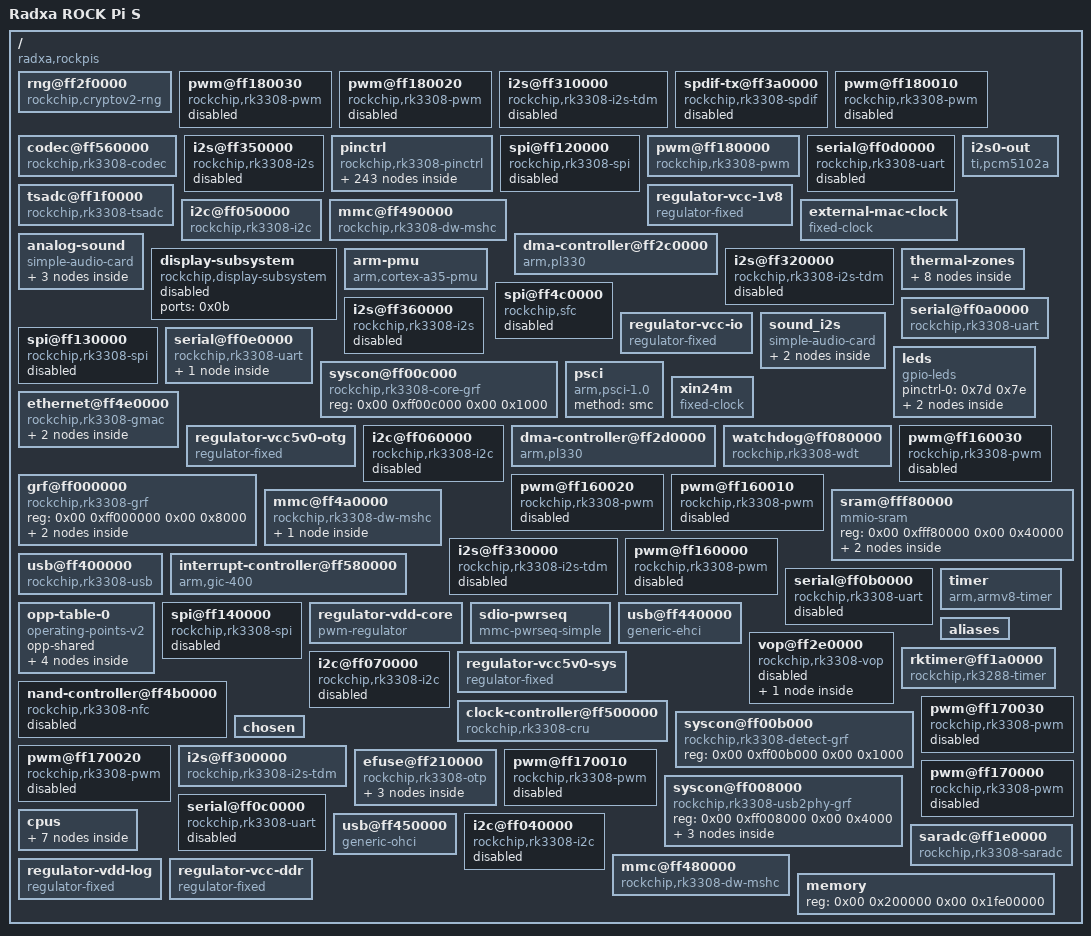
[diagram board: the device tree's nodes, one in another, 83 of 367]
/dts-v1/;

/ {
	#address-cells = <0x02>;
	model = "Radxa ROCK Pi S";
	serial-number = "f860772dc3d76db9";
	#size-cells = <0x02>;
	interrupt-parent = <0x01>;
	compatible = "radxa,rockpis", "rockchip,rk3308";

	rng@ff2f0000 {
		clock-names = "clk_crypto", "clk_crypto_apk", "aclk_crypto", "hclk_crypto";
		assigned-clocks = <0x02 0x29 0x02 0x2a 0x02 0x87 0x02 0xab>;
		assigned-clock-rates = <0x8f0d180 0x8f0d180 0xbebc200 0x5f5e100>;
		resets = <0x02 0x24>;
		clocks = <0x02 0x29 0x02 0x2a 0x02 0x87 0x02 0xab>;
		compatible = "rockchip,cryptov2-rng";
		reg = <0x00 0xff2f0000 0x00 0x4000>;
		phandle = <0x87>;
		reset-names = "reset";
	};

	pwm@ff180030 {
		pinctrl-names = "default";
		pinctrl-0 = <0x3a>;
		clock-names = "pwm", "pclk";
		clocks = <0x02 0x1a 0x02 0xce>;
		#pwm-cells = <0x03>;
		compatible = "rockchip,rk3308-pwm", "rockchip,rk3328-pwm";
		status = "disabled";
		reg = <0x00 0xff180030 0x00 0x10>;
		phandle = <0xa2>;
	};

	pwm@ff180020 {
		pinctrl-names = "default";
		pinctrl-0 = <0x39>;
		clock-names = "pwm", "pclk";
		clocks = <0x02 0x1a 0x02 0xce>;
		#pwm-cells = <0x03>;
		compatible = "rockchip,rk3308-pwm", "rockchip,rk3328-pwm";
		status = "disabled";
		reg = <0x00 0xff180020 0x00 0x10>;
		phandle = <0xa1>;
	};

	i2s@ff310000 {
		rockchip,cru = <0x02>;
		clock-names = "mclk_tx", "mclk_rx", "hclk", "mclk_tx_src", "mclk_rx_src", "mclk_root0", "mclk_root1";
		rockchip,io-multiplex;
		resets = <0x02 0x8c 0x02 0x8d>;
		interrupts = <0x00 0x31 0x04>;
		clocks = <0x02 0x50 0x02 0x52 0x02 0xa5 0x02 0x70 0x02 0x71 0x02 0x03 0x02 0x04>;
		rockchip,mclk-calibrate;
		dma-names = "tx", "rx";
		compatible = "rockchip,rk3308-i2s-tdm";
		status = "disabled";
		rockchip,grf = <0x3d>;
		reg = <0x00 0xff310000 0x00 0x1000>;
		phandle = <0xb0>;
		dmas = <0x1b 0x02 0x1b 0x03>;
		reset-names = "tx-m", "rx-m";
	};

	spdif-tx@ff3a0000 {
		pinctrl-names = "default";
		pinctrl-0 = <0x52>;
		clock-names = "mclk", "hclk";
		interrupts = <0x00 0x37 0x04>;
		clocks = <0x02 0x62 0x02 0xa2>;
		dma-names = "tx";
		compatible = "rockchip,rk3308-spdif", "rockchip,rk3066-spdif";
		status = "disabled";
		reg = <0x00 0xff3a0000 0x00 0x1000>;
		phandle = <0xb4>;
		dmas = <0x1b 0x0d>;
	};

	pwm@ff180010 {
		pinctrl-names = "default";
		pinctrl-0 = <0x38>;
		clock-names = "pwm", "pclk";
		clocks = <0x02 0x1a 0x02 0xce>;
		#pwm-cells = <0x03>;
		compatible = "rockchip,rk3308-pwm", "rockchip,rk3328-pwm";
		status = "disabled";
		reg = <0x00 0xff180010 0x00 0x10>;
		phandle = <0xa0>;
	};

	codec@ff560000 {
		rockchip,detect-grf = <0x71>;
		clock-names = "mclk_tx", "mclk_rx", "acodec";
		resets = <0x02 0x99>;
		interrupts = <0x01 0x72 0x04 0x01 0x73 0x04>;
		clocks = <0x02 0x55 0x02 0x57 0x02 0xc4>;
		#sound-dai-cells = <0x00>;
		compatible = "rockchip,rk3308-codec";
		status = "okay";
		rockchip,grf = <0x3d>;
		reg = <0x00 0xff560000 0x00 0x10000>;
		phandle = <0x80>;
		reset-names = "acodec-reset";
	};

	i2s@ff350000 {
		pinctrl-names = "default";
		pinctrl-0 = <0x4e 0x4f 0x50 0x51>;
		clock-names = "i2s_clk", "i2s_hclk";
		resets = <0x02 0x95 0x02 0x94>;
		interrupts = <0x00 0x34 0x04>;
		clocks = <0x02 0x5c 0x02 0xa8>;
		dma-names = "tx", "rx";
		compatible = "rockchip,rk3308-i2s", "rockchip,rk3066-i2s";
		status = "disabled";
		reg = <0x00 0xff350000 0x00 0x1000>;
		phandle = <0xb2>;
		dmas = <0x1b 0x08 0x1b 0x09>;
		reset-names = "reset-m", "reset-h";
	};

	pinctrl {
		pinctrl-names = "default";
		#address-cells = <0x02>;
		pinctrl-0 = <0x72>;
		#size-cells = <0x02>;
		compatible = "rockchip,rk3308-pinctrl";
		ranges;
		rockchip,grf = <0x3d>;
		phandle = <0xc1>;

		pwm9 {

			pwm9-pin-pull-down {
				rockchip,pins = <0x02 0x0b 0x02 0x79>;
				phandle = <0x105>;
			};

			pwm9-pin {
				rockchip,pins = <0x02 0x0b 0x02 0x75>;
				phandle = <0x30>;
			};
		};

		pdm_m1 {

			pdm-m1-sdi2 {
				rockchip,pins = <0x01 0x13 0x04 0x75>;
				phandle = <0xf4>;
			};

			pdm-m1-sdi0 {
				rockchip,pins = <0x01 0x15 0x04 0x75>;
				phandle = <0xf2>;
			};

			pdm-m1-clk {
				rockchip,pins = <0x01 0x0e 0x04 0x75>;
				phandle = <0xf1>;
			};

			pdm-m1-sdi3 {
				rockchip,pins = <0x01 0x12 0x04 0x75>;
				phandle = <0xf5>;
			};

			pdm-m1-sdi1 {
				rockchip,pins = <0x01 0x14 0x04 0x75>;
				phandle = <0xf3>;
			};
		};

		gmac-m1 {

			macm1-refclk-12ma {
				rockchip,pins = <0x04 0x0c 0x02 0x77>;
				phandle = <0xd3>;
			};

			macm1-refclk {
				rockchip,pins = <0x04 0x0c 0x02 0x75>;
				phandle = <0xd4>;
			};

			rmiim1-pins {
				rockchip,pins = <0x04 0x0f 0x02 0x77 0x04 0x05 0x02 0x77 0x04 0x04 0x02 0x77 0x04 0x02 0x02 0x75 0x04 0x03 0x02 0x75 0x04 0x00 0x02 0x75 0x04 0x01 0x02 0x75 0x04 0x0e 0x02 0x75 0x04 0x0d 0x02 0x75>;
				phandle = <0xd2>;
			};
		};

		spdif_out {

			spdif-out {
				rockchip,pins = <0x00 0x11 0x01 0x75>;
				phandle = <0x52>;
			};
		};

		spi2 {

			spi2-clk {
				rockchip,pins = <0x01 0x18 0x03 0x7b>;
				phandle = <0x2b>;
			};

			spi2-csn0 {
				rockchip,pins = <0x01 0x19 0x03 0x7b>;
				phandle = <0x2c>;
			};

			spi2-mosi {
				rockchip,pins = <0x01 0x17 0x03 0x7b>;
				phandle = <0x2e>;
			};

			spi2-miso {
				rockchip,pins = <0x01 0x16 0x03 0x7b>;
				phandle = <0x2d>;
			};
		};

		pcfg-pull-none-12ma {
			drive-strength = <0x0c>;
			bias-disable;
			phandle = <0x77>;
		};

		i2c1 {

			i2c1-xfer {
				rockchip,pins = <0x00 0x0b 0x01 0x78 0x00 0x0c 0x01 0x78>;
				phandle = <0x11>;
			};
		};

		pwm7 {

			pwm7-pin-pull-down {
				rockchip,pins = <0x02 0x08 0x02 0x79>;
				phandle = <0x103>;
			};

			pwm7-pin {
				rockchip,pins = <0x02 0x08 0x02 0x75>;
				phandle = <0x36>;
			};
		};

		gmac {

			mac-refclk {
				rockchip,pins = <0x01 0x0c 0x03 0x75>;
				phandle = <0xd1>;
			};

			rmii-pins {
				rockchip,pins = <0x01 0x11 0x03 0x77 0x01 0x13 0x03 0x77 0x01 0x12 0x03 0x77 0x01 0x14 0x03 0x75 0x01 0x15 0x03 0x75 0x01 0x0f 0x03 0x75 0x01 0x10 0x03 0x75 0x01 0x0e 0x03 0x75 0x01 0x0d 0x03 0x75>;
				phandle = <0x69>;
			};

			mac-refclk-12ma {
				rockchip,pins = <0x01 0x0c 0x03 0x77>;
				phandle = <0x6a>;
			};

			mac-rst {
				rockchip,pins = <0x00 0x07 0x00 0x75>;
				phandle = <0x6c>;
			};
		};

		i2s_8ch_0 {

			i2s-8ch-0-sdo2 {
				rockchip,pins = <0x02 0x0b 0x01 0x75>;
				phandle = <0x4b>;
			};

			i2s-8ch-0-sdo0 {
				rockchip,pins = <0x02 0x09 0x01 0x75>;
				phandle = <0x49>;
			};

			i2s-8ch-0-sdi2 {
				rockchip,pins = <0x02 0x0f 0x01 0x75>;
				phandle = <0x47>;
			};

			i2s-8ch-0-sdi0 {
				rockchip,pins = <0x02 0x0d 0x01 0x75>;
				phandle = <0x45>;
			};

			i2s-8ch-0-sdo3 {
				rockchip,pins = <0x02 0x0c 0x01 0x75>;
				phandle = <0x4c>;
			};

			i2s-8ch-0-sdo1 {
				rockchip,pins = <0x02 0x0a 0x01 0x75>;
				phandle = <0x4a>;
			};

			i2s-8ch-0-lrcktx {
				rockchip,pins = <0x02 0x07 0x01 0x75>;
				phandle = <0x43>;
			};

			i2s-8ch-0-sdi3 {
				rockchip,pins = <0x02 0x10 0x01 0x75>;
				phandle = <0x48>;
			};

			i2s-8ch-0-lrckrx {
				rockchip,pins = <0x02 0x08 0x01 0x75>;
				phandle = <0x44>;
			};

			i2s-8ch-0-mclk {
				rockchip,pins = <0x02 0x04 0x01 0x75>;
				phandle = <0x4d>;
			};

			i2s-8ch-0-sclktx {
				rockchip,pins = <0x02 0x05 0x01 0x75>;
				phandle = <0x41>;
			};

			i2s-8ch-0-sdi1 {
				rockchip,pins = <0x02 0x0e 0x01 0x75>;
				phandle = <0x46>;
			};

			i2s-8ch-0-sclkrx {
				rockchip,pins = <0x02 0x06 0x01 0x75>;
				phandle = <0x42>;
			};
		};

		gpio@ff230000 {
			gpio-controller;
			gpio-line-names = "", "", "", "", "", "", "", "", "", "", "", "", "", "", "", "", "", "", "", "", "", "", "header1-pin21 [GPIO1_C6]", "header1-pin19 [GPIO1_C7]", "header1-pin23 [GPIO1_D0]", "header1-pin24 [GPIO1_D1]", "", "", "", "", "", "";
			interrupts = <0x00 0x29 0x04>;
			clocks = <0x02 0xd8>;
			compatible = "rockchip,gpio-bank";
			#interrupt-cells = <0x02>;
			reg = <0x00 0xff230000 0x00 0x100>;
			phandle = <0xc2>;
			#gpio-cells = <0x02>;
			interrupt-controller;
		};

		i2s_8ch_1_m0 {

			i2s-8ch-1-m0-sdo3_sdi1 {
				rockchip,pins = <0x01 0x0a 0x02 0x75>;
				phandle = <0xe0>;
			};

			i2s-8ch-1-m0-sdo0 {
				rockchip,pins = <0x01 0x07 0x02 0x75>;
				phandle = <0xdd>;
			};

			i2s-8ch-1-m0-sdo1-sdi3 {
				rockchip,pins = <0x01 0x08 0x02 0x75>;
				phandle = <0xde>;
			};

			i2s-8ch-1-m0-lrcktx {
				rockchip,pins = <0x01 0x05 0x02 0x75>;
				phandle = <0xdb>;
			};

			i2s-8ch-1-m0-lrckrx {
				rockchip,pins = <0x01 0x06 0x02 0x75>;
				phandle = <0xdc>;
			};

			i2s-8ch-1-m0-sdi0 {
				rockchip,pins = <0x01 0x0b 0x02 0x75>;
				phandle = <0xe1>;
			};

			i2s-8ch-1-m0-sclktx {
				rockchip,pins = <0x01 0x03 0x02 0x75>;
				phandle = <0xd9>;
			};

			i2s-8ch-1-m0-sclkrx {
				rockchip,pins = <0x01 0x04 0x02 0x75>;
				phandle = <0xda>;
			};

			i2s-8ch-1-m0-sdo2-sdi2 {
				rockchip,pins = <0x01 0x09 0x02 0x75>;
				phandle = <0xdf>;
			};

			i2s-8ch-1-m0-mclk {
				rockchip,pins = <0x01 0x02 0x02 0x75>;
				phandle = <0xd8>;
			};
		};

		spi0 {

			spi0-miso {
				rockchip,pins = <0x02 0x00 0x02 0x7b>;
				phandle = <0x25>;
			};

			spi0-csn0 {
				rockchip,pins = <0x02 0x03 0x02 0x7b>;
				phandle = <0x24>;
			};

			spi0-clk {
				rockchip,pins = <0x02 0x02 0x02 0x7b>;
				phandle = <0x23>;
			};

			spi0-mosi {
				rockchip,pins = <0x02 0x01 0x02 0x7b>;
				phandle = <0x26>;
			};
		};

		pcfg-pull-down-4ma {
			drive-strength = <0x04>;
			bias-pull-down;
			phandle = <0xc7>;
		};

		pwm5 {

			pwm5-pin-pull-down {
				rockchip,pins = <0x00 0x11 0x02 0x79>;
				phandle = <0x101>;
			};

			pwm5-pin {
				rockchip,pins = <0x00 0x11 0x02 0x75>;
				phandle = <0x34>;
			};
		};

		pcfg-pull-none-2ma {
			drive-strength = <0x02>;
			bias-disable;
			phandle = <0xc5>;
		};

		pwm10 {

			pwm10-pin-pull-down {
				rockchip,pins = <0x02 0x0c 0x02 0x79>;
				phandle = <0x106>;
			};

			pwm10-pin {
				rockchip,pins = <0x02 0x0c 0x02 0x75>;
				phandle = <0x31>;
			};
		};

		pcfg-pull-down {
			bias-pull-down;
			phandle = <0x79>;
		};

		uart4 {

			uart4-cts {
				rockchip,pins = <0x04 0x06 0x01 0x75>;
				phandle = <0x1d>;
			};

			uart4-xfer {
				rockchip,pins = <0x04 0x09 0x01 0x7c 0x04 0x08 0x01 0x7c>;
				phandle = <0x1c>;
			};

			uart4-rts-pin {
				rockchip,pins = <0x04 0x07 0x00 0x75>;
				phandle = <0x118>;
			};

			uart4-rts {
				rockchip,pins = <0x04 0x07 0x01 0x75>;
				phandle = <0x1e>;
			};
		};

		uart2-m0 {

			uart2m0-xfer {
				rockchip,pins = <0x01 0x17 0x02 0x7c 0x01 0x16 0x02 0x7c>;
				phandle = <0x19>;
			};
		};

		pwm3 {

			pwm3-pin-pull-down {
				rockchip,pins = <0x00 0x10 0x01 0x79>;
				phandle = <0xff>;
			};

			pwm3-pin {
				rockchip,pins = <0x00 0x10 0x01 0x75>;
				phandle = <0x3a>;
			};
		};

		lcdc {

			lcdc-rgb888-m1 {
				rockchip,pins = <0x03 0x06 0x03 0x75 0x03 0x07 0x03 0x75 0x03 0x08 0x03 0x75 0x03 0x09 0x03 0x75 0x03 0x0a 0x04 0x75 0x03 0x0b 0x04 0x75>;
				phandle = <0x11a>;
			};

			lcdc-ctl {
				rockchip,pins = <0x01 0x00 0x01 0x77 0x01 0x01 0x01 0x75 0x01 0x02 0x01 0x75 0x01 0x03 0x01 0x75 0x01 0x04 0x01 0x75 0x01 0x05 0x01 0x75 0x01 0x06 0x01 0x75 0x01 0x07 0x01 0x75 0x01 0x08 0x01 0x75 0x01 0x09 0x01 0x75 0x01 0x0a 0x01 0x75 0x01 0x0b 0x01 0x75 0x01 0x0c 0x01 0x75 0x01 0x0d 0x01 0x75 0x01 0x0e 0x01 0x75 0x01 0x0f 0x01 0x75 0x01 0x10 0x01 0x75 0x01 0x11 0x01 0x75 0x01 0x12 0x01 0x75 0x01 0x13 0x01 0x75 0x01 0x14 0x01 0x75 0x01 0x15 0x01 0x75>;
				phandle = <0x40>;
			};

			lcdc-rgb888-m0 {
				rockchip,pins = <0x01 0x16 0x06 0x75 0x01 0x17 0x06 0x75 0x02 0x09 0x03 0x75 0x02 0x0a 0x03 0x75 0x02 0x0f 0x03 0x75 0x02 0x10 0x03 0x75>;
				phandle = <0x119>;
			};
		};

		gpio@ff240000 {
			gpio-controller;
			gpio-line-names = "header1-pin10 [GPIO2_A0]", "header1-pin8 [GPIO2_A1]", "", "", "header1-pin7 [GPIO2_A4]", "header1-pin12 [GPIO2_A5]", "header2-pin46 [GPIO2_A6]", "header1-pin22 [GPIO1_A7]", "header2-pin45 [GPIO2_B0]", "header1-pin18 [GPIO2_B1]", "header1-pin16 [GPIO2_B2]", "header2-pin44 [GPIO2_B3]", "header2-pin43 [GPIO2_B4]", "header2-pin28 [GPIO2_B5]", "header2-pin30 [GPIO2_B6]", "header2-pin32 [GPIO2_B7]", "header2-pin34 [GPIO2_C0]", "", "", "", "", "", "", "", "", "", "", "", "", "", "", "";
			interrupts = <0x00 0x2a 0x04>;
			clocks = <0x02 0xd9>;
			compatible = "rockchip,gpio-bank";
			#interrupt-cells = <0x02>;
			reg = <0x00 0xff240000 0x00 0x100>;
			phandle = <0xc3>;
			#gpio-cells = <0x02>;
			interrupt-controller;
		};

		pcfg-pull-none-8ma {
			drive-strength = <0x08>;
			bias-disable;
			phandle = <0x73>;
		};

		uart3-m1 {

			uart3m1-xfer {
				rockchip,pins = <0x00 0x12 0x03 0x7c 0x00 0x11 0x03 0x7c>;
				phandle = <0x117>;
			};
		};

		leds {

			heartbeat-led {
				rockchip,pins = <0x00 0x05 0x00 0x75>;
				phandle = <0x7e>;
			};

			green-led {
				rockchip,pins = <0x00 0x06 0x00 0x75>;
				phandle = <0x7d>;
			};
		};

		pwm1 {

			pwm1-pin {
				rockchip,pins = <0x00 0x0e 0x01 0x75>;
				phandle = <0x38>;
			};

			pwm1-pin-pull-down {
				rockchip,pins = <0x00 0x0e 0x01 0x79>;
				phandle = <0xfd>;
			};
		};

		tsadc {

			tsadc-otp-out {
				rockchip,pins = <0x00 0x0a 0x01 0x75>;
				phandle = <0x3f>;
			};

			tsadc-otp-pin {
				rockchip,pins = <0x00 0x0a 0x00 0x75>;
				phandle = <0x3e>;
			};
		};

		i2c3-m2 {

			i2c3m2-xfer {
				rockchip,pins = <0x02 0x01 0x03 0x78 0x02 0x00 0x03 0x78>;
				phandle = <0xd6>;
			};
		};

		uart0 {

			uart0-rts-pin {
				rockchip,pins = <0x02 0x03 0x00 0x75>;
				phandle = <0x115>;
			};

			uart0-cts {
				rockchip,pins = <0x02 0x02 0x01 0x75>;
				phandle = <0x113>;
			};

			uart0-rts {
				rockchip,pins = <0x02 0x03 0x01 0x75>;
				phandle = <0x114>;
			};

			uart0-xfer {
				rockchip,pins = <0x02 0x01 0x01 0x7c 0x02 0x00 0x01 0x7c>;
				phandle = <0x15>;
			};
		};

		emmc {

			emmc-rstn {
				rockchip,pins = <0x03 0x0a 0x02 0x75>;
				phandle = <0xcd>;
			};

			emmc-clk {
				rockchip,pins = <0x03 0x09 0x02 0x73>;
				phandle = <0x5a>;
			};

			emmc-bus1 {
				rockchip,pins = <0x03 0x00 0x02 0x74>;
				phandle = <0xce>;
			};

			emmc-bus8 {
				rockchip,pins = <0x03 0x00 0x02 0x74 0x03 0x01 0x02 0x74 0x03 0x02 0x02 0x74 0x03 0x03 0x02 0x74 0x03 0x04 0x02 0x74 0x03 0x05 0x02 0x74 0x03 0x06 0x02 0x74 0x03 0x07 0x02 0x74>;
				phandle = <0x59>;
			};

			emmc-bus4 {
				rockchip,pins = <0x03 0x00 0x02 0x74 0x03 0x01 0x02 0x74 0x03 0x02 0x02 0x74 0x03 0x03 0x02 0x74>;
				phandle = <0xcf>;
			};

			emmc-pwren {
				rockchip,pins = <0x03 0x0b 0x02 0x75>;
				phandle = <0xcc>;
			};

			emmc-cmd {
				rockchip,pins = <0x03 0x08 0x02 0x74>;
				phandle = <0x5b>;
			};
		};

		pdm_m2 {

			pdm-m2-sdi3 {
				rockchip,pins = <0x02 0x10 0x02 0x75>;
				phandle = <0xfb>;
			};

			pdm-m2-sdi1 {
				rockchip,pins = <0x02 0x0e 0x02 0x75>;
				phandle = <0xf9>;
			};

			pdm-m2-clk {
				rockchip,pins = <0x02 0x06 0x02 0x75>;
				phandle = <0xf7>;
			};

			pdm-m2-sdi2 {
				rockchip,pins = <0x02 0x0f 0x02 0x75>;
				phandle = <0xfa>;
			};

			pdm-m2-sdi0 {
				rockchip,pins = <0x02 0x0d 0x02 0x75>;
				phandle = <0xf8>;
			};

			pdm-m2-clkm {
				rockchip,pins = <0x02 0x04 0x03 0x75>;
				phandle = <0xf6>;
			};
		};

		spdif_in {

			spdif-in {
				rockchip,pins = <0x00 0x12 0x01 0x75>;
				phandle = <0x10e>;
			};
		};

		pcfg-output-high {
			output-high;
			phandle = <0xc8>;
		};

		pcfg-pull-up {
			phandle = <0x7c>;
			bias-pull-up;
		};

		i2c3-m0 {

			i2c3m0-xfer {
				rockchip,pins = <0x00 0x0f 0x02 0x78 0x00 0x10 0x02 0x78>;
				phandle = <0x13>;
			};
		};

		pcfg-input {
			phandle = <0xcb>;
			input-enable;
		};

		pcfg-pull-up-2ma {
			drive-strength = <0x02>;
			phandle = <0xc6>;
			bias-pull-up;
		};

		i2c2 {

			i2c2-xfer {
				rockchip,pins = <0x02 0x02 0x03 0x78 0x02 0x03 0x03 0x78>;
				phandle = <0x12>;
			};
		};

		pwm8 {

			pwm8-pin {
				rockchip,pins = <0x02 0x0a 0x02 0x75>;
				phandle = <0x2f>;
			};

			pwm8-pin-pull-down {
				rockchip,pins = <0x02 0x0a 0x02 0x79>;
				phandle = <0x104>;
			};
		};

		i2s_2ch_0 {

			i2s-2ch-0-sdo {
				rockchip,pins = <0x04 0x0f 0x01 0x75>;
				phandle = <0x51>;
			};

			i2s-2ch-0-sclk {
				rockchip,pins = <0x04 0x0d 0x01 0x75>;
				phandle = <0x4e>;
			};

			i2s-2ch-0-sdi {
				rockchip,pins = <0x04 0x10 0x01 0x75>;
				phandle = <0x50>;
			};

			i2s-2ch-0-lrck {
				rockchip,pins = <0x04 0x0e 0x01 0x75>;
				phandle = <0x4f>;
			};

			i2s-2ch-0-mclk {
				rockchip,pins = <0x04 0x0c 0x01 0x75>;
				phandle = <0xd7>;
			};
		};

		pcfg-pull-none {
			bias-disable;
			phandle = <0x75>;
		};

		pdm_m0 {

			pdm-m0-clk {
				rockchip,pins = <0x01 0x04 0x03 0x75>;
				phandle = <0xec>;
			};

			pdm-m0-sdi2 {
				rockchip,pins = <0x01 0x09 0x03 0x75>;
				phandle = <0xef>;
			};

			pdm-m0-sdi0 {
				rockchip,pins = <0x01 0x0b 0x03 0x75>;
				phandle = <0xed>;
			};

			pdm-m0-sdi3 {
				rockchip,pins = <0x01 0x08 0x03 0x75>;
				phandle = <0xf0>;
			};

			pdm-m0-sdi1 {
				rockchip,pins = <0x01 0x0a 0x03 0x75>;
				phandle = <0xee>;
			};
		};

		pcfg-pull-none-4ma {
			drive-strength = <0x04>;
			bias-disable;
			phandle = <0x7a>;
		};

		i2s_8ch_1_m1 {

			i2s-8ch-1-m1-sdo0 {
				rockchip,pins = <0x01 0x11 0x02 0x75>;
				phandle = <0xe7>;
			};

			i2s-8ch-1-m1-sdo2-sdi2 {
				rockchip,pins = <0x01 0x13 0x02 0x75>;
				phandle = <0xe9>;
			};

			i2s-8ch-1-m1-sdi0 {
				rockchip,pins = <0x01 0x15 0x02 0x75>;
				phandle = <0xeb>;
			};

			i2s-8ch-1-m1-lrcktx {
				rockchip,pins = <0x01 0x0f 0x02 0x75>;
				phandle = <0xe5>;
			};

			i2s-8ch-1-m1-lrckrx {
				rockchip,pins = <0x01 0x10 0x02 0x75>;
				phandle = <0xe6>;
			};

			i2s-8ch-1-m1-sdo3_sdi1 {
				rockchip,pins = <0x01 0x14 0x02 0x75>;
				phandle = <0xea>;
			};

			i2s-8ch-1-m1-sclktx {
				rockchip,pins = <0x01 0x0d 0x02 0x75>;
				phandle = <0xe3>;
			};

			i2s-8ch-1-m1-sclkrx {
				rockchip,pins = <0x01 0x0e 0x02 0x75>;
				phandle = <0xe4>;
			};

			i2s-8ch-1-m1-mclk {
				rockchip,pins = <0x01 0x0c 0x02 0x75>;
				phandle = <0xe2>;
			};

			i2s-8ch-1-m1-sdo1-sdi3 {
				rockchip,pins = <0x01 0x12 0x02 0x75>;
				phandle = <0xe8>;
			};
		};

		sfc {

			sfc-bus4 {
				rockchip,pins = <0x03 0x00 0x03 0x75 0x03 0x01 0x03 0x75 0x03 0x02 0x03 0x75 0x03 0x03 0x03 0x75>;
				phandle = <0x6f>;
			};

			sfc-bus2 {
				rockchip,pins = <0x03 0x00 0x03 0x75 0x03 0x01 0x03 0x75>;
				phandle = <0xd0>;
			};

			sfc-clk {
				rockchip,pins = <0x03 0x05 0x03 0x75>;
				phandle = <0x6d>;
			};

			sfc-cs0 {
				rockchip,pins = <0x03 0x04 0x03 0x75>;
				phandle = <0x6e>;
			};
		};

		spi1 {

			spi1-miso {
				rockchip,pins = <0x03 0x0a 0x03 0x7b>;
				phandle = <0x29>;
			};

			spi1-csn0 {
				rockchip,pins = <0x03 0x0d 0x03 0x7b>;
				phandle = <0x28>;
			};

			spi1-mosi {
				rockchip,pins = <0x03 0x0c 0x03 0x7b>;
				phandle = <0x2a>;
			};

			spi1-clk {
				rockchip,pins = <0x03 0x0b 0x03 0x7b>;
				phandle = <0x27>;
			};
		};

		sdio-pwrseq {

			wifi-host-wake {
				rockchip,pins = <0x00 0x00 0x00 0x79>;
				phandle = <0x61>;
			};

			wifi-enable-h {
				rockchip,pins = <0x00 0x02 0x00 0x75>;
				phandle = <0x81>;
			};
		};

		bluetooth {

			bt-reg-on {
				rockchip,pins = <0x04 0x0b 0x00 0x75>;
				phandle = <0x20>;
			};

			host-wake-bt {
				rockchip,pins = <0x04 0x0a 0x00 0x75>;
				phandle = <0x22>;
			};

			bt-wake-host {
				rockchip,pins = <0x04 0x0c 0x00 0x79>;
				phandle = <0x21>;
			};
		};

		usb {

			otg-vbus-drv {
				rockchip,pins = <0x00 0x15 0x00 0x75>;
				phandle = <0x83>;
			};
		};

		pcfg-pull-none-smt {
			bias-disable;
			input-schmitt-enable;
			phandle = <0x78>;
		};

		gpio@ff250000 {
			gpio-controller;
			gpio-line-names = "", "", "", "", "", "", "", "", "", "", "header2-pin42 [GPIO3_B2]", "header2-pin41 [GPIO3_B3]", "header2-pin40 [GPIO3_B4]", "header2-pin39 [GPIO3_B5]", "", "", "", "", "", "", "", "", "", "", "", "", "", "", "", "", "", "";
			interrupts = <0x00 0x2b 0x04>;
			clocks = <0x02 0xda>;
			compatible = "rockchip,gpio-bank";
			#interrupt-cells = <0x02>;
			reg = <0x00 0xff250000 0x00 0x100>;
			phandle = <0xc4>;
			#gpio-cells = <0x02>;
			interrupt-controller;
		};

		sdmmc {

			sdmmc-bus1 {
				rockchip,pins = <0x04 0x18 0x01 0x7b>;
				phandle = <0x109>;
			};

			sdmmc-det {
				rockchip,pins = <0x00 0x03 0x01 0x7b>;
				phandle = <0x57>;
			};

			sdmmc-pwren {
				rockchip,pins = <0x04 0x1e 0x01 0x7a>;
				phandle = <0x108>;
			};

			sdmmc-bus4 {
				rockchip,pins = <0x04 0x18 0x01 0x7b 0x04 0x19 0x01 0x7b 0x04 0x1a 0x01 0x7b 0x04 0x1b 0x01 0x7b>;
				phandle = <0x58>;
			};

			sdmmc-cmd {
				rockchip,pins = <0x04 0x1c 0x01 0x7b>;
				phandle = <0x56>;
			};

			sdmmc-clk {
				rockchip,pins = <0x04 0x1d 0x01 0x7a>;
				phandle = <0x55>;
			};
		};

		i2c0 {

			i2c0-xfer {
				rockchip,pins = <0x01 0x18 0x02 0x78 0x01 0x19 0x02 0x78>;
				phandle = <0x10>;
			};
		};

		pwm6 {

			pwm6-pin {
				rockchip,pins = <0x00 0x12 0x02 0x75>;
				phandle = <0x35>;
			};

			pwm6-pin-pull-down {
				rockchip,pins = <0x00 0x12 0x02 0x79>;
				phandle = <0x102>;
			};
		};

		pwm11 {

			pwm11-pin-pull-down {
				rockchip,pins = <0x02 0x10 0x04 0x79>;
				phandle = <0x107>;
			};

			pwm11-pin {
				rockchip,pins = <0x02 0x10 0x04 0x75>;
				phandle = <0x32>;
			};
		};

		sdio {

			sdio-intn {
				rockchip,pins = <0x00 0x00 0x01 0x73>;
				phandle = <0x10c>;
			};

			sdio-cmd {
				rockchip,pins = <0x04 0x04 0x01 0x74>;
				phandle = <0x5d>;
			};

			sdio-bus1 {
				rockchip,pins = <0x04 0x00 0x01 0x74>;
				phandle = <0x10d>;
			};

			sdio-clk {
				rockchip,pins = <0x04 0x05 0x01 0x73>;
				phandle = <0x5e>;
			};

			sdio-bus4 {
				rockchip,pins = <0x04 0x00 0x01 0x74 0x04 0x01 0x01 0x74 0x04 0x02 0x01 0x74 0x04 0x03 0x01 0x74>;
				phandle = <0x5c>;
			};

			sdio-wrpt {
				rockchip,pins = <0x00 0x01 0x01 0x73>;
				phandle = <0x10b>;
			};

			sdio-pwren {
				rockchip,pins = <0x00 0x02 0x01 0x73>;
				phandle = <0x10a>;
			};
		};

		pcfg-input-high {
			phandle = <0xca>;
			bias-pull-up;
			input-enable;
		};

		flash {

			flash-bus8 {
				rockchip,pins = <0x03 0x00 0x01 0x76 0x03 0x01 0x01 0x76 0x03 0x02 0x01 0x76 0x03 0x03 0x01 0x76 0x03 0x04 0x01 0x76 0x03 0x05 0x01 0x76 0x03 0x06 0x01 0x76 0x03 0x07 0x01 0x76>;
				phandle = <0x63>;
			};

			flash-rdn {
				rockchip,pins = <0x03 0x0a 0x01 0x75>;
				phandle = <0x66>;
			};

			flash-ale {
				rockchip,pins = <0x03 0x0b 0x01 0x75>;
				phandle = <0x62>;
			};

			flash-csn0 {
				rockchip,pins = <0x03 0x0d 0x01 0x75>;
				phandle = <0x65>;
			};

			flash-rdy {
				rockchip,pins = <0x03 0x0c 0x01 0x75>;
				phandle = <0x67>;
			};

			flash-cle {
				rockchip,pins = <0x03 0x09 0x01 0x75>;
				phandle = <0x64>;
			};

			flash-wrn {
				rockchip,pins = <0x03 0x08 0x01 0x75>;
				phandle = <0x68>;
			};
		};

		pcfg-pull-up-8ma {
			drive-strength = <0x08>;
			phandle = <0x74>;
			bias-pull-up;
		};

		uart2-m1 {

			uart2m1-xfer {
				rockchip,pins = <0x04 0x1b 0x02 0x7c 0x04 0x1a 0x02 0x7c>;
				phandle = <0x116>;
			};
		};

		pwm4 {

			pwm4-pin {
				rockchip,pins = <0x00 0x01 0x02 0x75>;
				phandle = <0x33>;
			};

			pwm4-pin-pull-down {
				rockchip,pins = <0x00 0x01 0x02 0x79>;
				phandle = <0x100>;
			};
		};

		uart3 {

			uart3-xfer {
				rockchip,pins = <0x03 0x0d 0x04 0x7c 0x03 0x0c 0x04 0x7c>;
				phandle = <0x1a>;
			};
		};

		pcfg-pull-up-12ma {
			drive-strength = <0x0c>;
			phandle = <0x76>;
			bias-pull-up;
		};

		pcfg-output-low {
			phandle = <0xc9>;
			output-low;
		};

		pwm2 {

			pwm2-pin {
				rockchip,pins = <0x00 0x0f 0x01 0x75>;
				phandle = <0x39>;
			};

			pwm2-pin-pull-down {
				rockchip,pins = <0x00 0x0f 0x01 0x79>;
				phandle = <0xfe>;
			};
		};

		gpio@ff220000 {
			gpio-controller;
			gpio-line-names = "", "", "", "", "", "", "", "", "", "", "", "header1-pin3 [GPIO0_B3]", "header1-pin5 [GPIO0_B4]", "", "", "header1-pin11 [GPIO0_B7]", "header1-pin13 [GPIO0_C0]", "header1-pin15 [GPIO0_C1]", "", "", "", "", "", "", "", "", "", "", "", "", "", "";
			interrupts = <0x00 0x28 0x04>;
			clocks = <0x02 0xd7>;
			compatible = "rockchip,gpio-bank";
			#interrupt-cells = <0x02>;
			reg = <0x00 0xff220000 0x00 0x100>;
			phandle = <0x60>;
			#gpio-cells = <0x02>;
			interrupt-controller;
		};

		uart1 {

			uart1-cts {
				rockchip,pins = <0x01 0x16 0x01 0x75>;
				phandle = <0x17>;
			};

			uart1-rts {
				rockchip,pins = <0x01 0x17 0x01 0x75>;
				phandle = <0x18>;
			};

			uart1-xfer {
				rockchip,pins = <0x01 0x19 0x01 0x7c 0x01 0x18 0x01 0x7c>;
				phandle = <0x16>;
			};
		};

		gpio@ff260000 {
			gpio-controller;
			interrupts = <0x00 0x2c 0x04>;
			clocks = <0x02 0xdb>;
			compatible = "rockchip,gpio-bank";
			#interrupt-cells = <0x02>;
			reg = <0x00 0xff260000 0x00 0x100>;
			phandle = <0x1f>;
			#gpio-cells = <0x02>;
			interrupt-controller;
		};

		spi1-m1 {

			spi1m1-csn0 {
				rockchip,pins = <0x02 0x09 0x02 0x7b>;
				phandle = <0x112>;
			};

			spi1m1-clk {
				rockchip,pins = <0x02 0x07 0x02 0x7b>;
				phandle = <0x111>;
			};

			spi1m1-mosi {
				rockchip,pins = <0x02 0x05 0x02 0x7b>;
				phandle = <0x110>;
			};

			spi1m1-miso {
				rockchip,pins = <0x02 0x04 0x02 0x7b>;
				phandle = <0x10f>;
			};
		};

		pcfg-pull-up-4ma {
			drive-strength = <0x04>;
			phandle = <0x7b>;
			bias-pull-up;
		};

		pwm0 {

			pwm0-pin-pull-down {
				rockchip,pins = <0x00 0x0d 0x01 0x79>;
				phandle = <0x37>;
			};

			pwm0-pin {
				rockchip,pins = <0x00 0x0d 0x01 0x75>;
				phandle = <0xfc>;
			};
		};

		rtc {

			rtc-32k {
				rockchip,pins = <0x00 0x13 0x01 0x75>;
				phandle = <0x72>;
			};
		};

		i2c3-m1 {

			i2c3m1-xfer {
				rockchip,pins = <0x03 0x0c 0x02 0x78 0x03 0x0d 0x02 0x78>;
				phandle = <0xd5>;
			};
		};
	};

	spi@ff120000 {
		pinctrl-names = "default";
		#address-cells = <0x01>;
		pinctrl-0 = <0x23 0x24 0x25 0x26>;
		clock-names = "spiclk", "apb_pclk";
		interrupts = <0x00 0x0f 0x04>;
		clocks = <0x02 0x1b 0x02 0xcf>;
		#size-cells = <0x00>;
		dma-names = "tx", "rx";
		compatible = "rockchip,rk3308-spi", "rockchip,rk3066-spi";
		status = "disabled";
		reg = <0x00 0xff120000 0x00 0x1000>;
		phandle = <0x95>;
		dmas = <0x14 0x00 0x14 0x01>;
	};

	pwm@ff180000 {
		pinctrl-names = "default";
		pinctrl-0 = <0x37>;
		clock-names = "pwm", "pclk";
		clocks = <0x02 0x1a 0x02 0xce>;
		#pwm-cells = <0x03>;
		compatible = "rockchip,rk3308-pwm", "rockchip,rk3328-pwm";
		status = "okay";
		reg = <0x00 0xff180000 0x00 0x10>;
		phandle = <0x84>;
	};

	serial@ff0d0000 {
		reg-io-width = <0x04>;
		pinctrl-names = "default";
		pinctrl-0 = <0x1a>;
		clock-names = "baudclk", "apb_pclk";
		interrupts = <0x00 0x15 0x04>;
		clocks = <0x02 0x14 0x02 0xc8>;
		dma-names = "tx", "rx";
		compatible = "rockchip,rk3308-uart", "snps,dw-apb-uart";
		status = "disabled";
		reg = <0x00 0xff0d0000 0x00 0x100>;
		phandle = <0x93>;
		dmas = <0x14 0x0a 0x14 0x0b>;
		reg-shift = <0x02>;
	};

	i2s0-out {
		#sound-dai-cells = <0x00>;
		compatible = "ti,pcm5102a";
		status = "okay";
		phandle = <0x11f>;
	};

	tsadc@ff1f0000 {
		pinctrl-names = "gpio", "otpout";
		pinctrl-0 = <0x3e>;
		clock-names = "tsadc", "apb_pclk";
		rockchip,hw-tshut-polarity = <0x01>;
		assigned-clocks = <0x02 0x24>;
		assigned-clock-rates = <0xc350>;
		resets = <0x02 0x48>;
		interrupts = <0x00 0x26 0x04>;
		rockchip,hw-tshut-mode = <0x00>;
		clocks = <0x02 0x24 0x02 0xd3>;
		#thermal-sensor-cells = <0x01>;
		compatible = "rockchip,rk3308-tsadc";
		pinctrl-1 = <0x3f>;
		status = "okay";
		rockchip,grf = <0x3d>;
		reg = <0x00 0xff1f0000 0x00 0x100>;
		phandle = <0x3b>;
		reset-names = "tsadc-apb";
		rockchip,hw-tshut-temp = <0x1d4c0>;
	};

	regulator-vcc-1v8 {
		regulator-max-microvolt = <0x1b7740>;
		regulator-boot-on;
		regulator-always-on;
		regulator-min-microvolt = <0x1b7740>;
		regulator-name = "vcc_1v8";
		compatible = "regulator-fixed";
		phandle = <0x0d>;
		vin-supply = <0x0c>;
	};

	i2c@ff050000 {
		pinctrl-names = "default";
		#address-cells = <0x01>;
		pinctrl-0 = <0x11>;
		clock-names = "i2c", "pclk";
		interrupts = <0x00 0x0c 0x04>;
		clocks = <0x02 0x17 0x02 0xcb>;
		#size-cells = <0x00>;
		compatible = "rockchip,rk3308-i2c", "rockchip,rk3399-i2c";
		status = "okay";
		reg = <0x00 0xff050000 0x00 0x1000>;
		phandle = <0x8c>;
	};

	mmc@ff490000 {
		fifo-depth = <0x100>;
		pinctrl-names = "default";
		pinctrl-0 = <0x59 0x5a 0x5b>;
		clock-names = "biu", "ciu", "ciu-drive", "ciu-sample";
		cap-sd-highspeed;
		bus-width = <0x08>;
		non-removable;
		no-sdio;
		interrupts = <0x00 0x4d 0x04>;
		clocks = <0x02 0x9c 0x02 0x3a 0x02 0x3b 0x02 0x3c>;
		vmmc-supply = <0x0c>;
		compatible = "rockchip,rk3308-dw-mshc", "rockchip,rk3288-dw-mshc";
		status = "okay";
		reg = <0x00 0xff490000 0x00 0x4000>;
		phandle = <0xb9>;
		max-frequency = <0x8f0d180>;
		cap-mmc-highspeed;
	};

	external-mac-clock {
		clock-output-names = "mac_clkin";
		#clock-cells = <0x00>;
		clock-frequency = <0x2faf080>;
		compatible = "fixed-clock";
		phandle = <0x86>;
	};

	dma-controller@ff2c0000 {
		clock-names = "apb_pclk";
		interrupts = <0x00 0x00 0x04 0x00 0x01 0x04>;
		clocks = <0x02 0x8a>;
		arm,pl330-periph-burst;
		compatible = "arm,pl330", "arm,primecell";
		reg = <0x00 0xff2c0000 0x00 0x4000>;
		phandle = <0x14>;
		#dma-cells = <0x01>;
	};

	analog-sound {
		simple-audio-card,name = "analog";
		simple-audio-card,format = "i2s";
		simple-audio-card,widgets = "Headphone", "Headphones";
		simple-audio-card,codec-hp-det;
		compatible = "simple-audio-card";
		phandle = <0x11b>;
		simple-audio-card,mclk-fs = <0x100>;

		simple-audio-card,dai-link@1 {
			format = "i2s";

			cpu {
				sound-dai = <0x7f>;
			};

			codec {
				sound-dai = <0x80>;
			};
		};
	};

	display-subsystem {
		ports = <0x0b>;
		compatible = "rockchip,display-subsystem";
		status = "disabled";
		phandle = <0x85>;
	};

	i2s@ff320000 {
		clock-names = "mclk_tx", "mclk_rx", "hclk";
		resets = <0x02 0x8f 0x02 0x90>;
		interrupts = <0x00 0x32 0x04>;
		clocks = <0x02 0x54 0x02 0x56 0x02 0xa6>;
		dma-names = "rx", "tx";
		#sound-dai-cells = <0x00>;
		compatible = "rockchip,rk3308-i2s-tdm";
		status = "disabled";
		rockchip,grf = <0x3d>;
		reg = <0x00 0xff320000 0x00 0x1000>;
		phandle = <0x7f>;
		dmas = <0x1b 0x05 0x1b 0x04>;
		reset-names = "tx-m", "rx-m";
	};

	arm-pmu {
		interrupt-affinity = <0x07 0x08 0x09 0x0a>;
		interrupts = <0x00 0x53 0x04 0x00 0x54 0x04 0x00 0x55 0x04 0x00 0x56 0x04>;
		compatible = "arm,cortex-a35-pmu";
	};

	thermal-zones {
		phandle = <0xa9>;

		soc-thermal {
			polling-delay = <0x3e8>;
			polling-delay-passive = <0x14>;
			thermal-sensors = <0x3b 0x01>;
			sustainable-power = <0x12c>;
			phandle = <0xaa>;

			trips {

				trip-point-0 {
					temperature = <0x11170>;
					hysteresis = <0x7d0>;
					type = "passive";
					phandle = <0xab>;
				};

				trip-point-1 {
					temperature = <0x14c08>;
					hysteresis = <0x7d0>;
					type = "passive";
					phandle = <0x3c>;
				};

				soc-crit {
					temperature = <0x1c138>;
					hysteresis = <0x7d0>;
					type = "critical";
					phandle = <0xac>;
				};
			};

			cooling-maps {

				map0 {
					trip = <0x3c>;
					cooling-device = <0x07 0xffffffff 0xffffffff>;
					contribution = <0x1000>;
				};
			};
		};

		logic-thermal {
			polling-delay = <0x3e8>;
			polling-delay-passive = <0x64>;
			thermal-sensors = <0x3b 0x00>;
			phandle = <0xad>;
		};
	};

	spi@ff4c0000 {
		pinctrl-names = "default";
		pinctrl-0 = <0x6d 0x6e 0x6f>;
		clock-names = "clk_sfc", "hclk_sfc";
		interrupts = <0x00 0x52 0x04>;
		clocks = <0x02 0x3d 0x02 0x9d>;
		compatible = "rockchip,sfc";
		status = "disabled";
		reg = <0x00 0xff4c0000 0x00 0x4000>;
		phandle = <0xbe>;
	};

	serial@ff0a0000 {
		reg-io-width = <0x04>;
		pinctrl-names = "default";
		pinctrl-0 = <0x15>;
		clock-names = "baudclk", "apb_pclk";
		interrupts = <0x00 0x12 0x04>;
		clocks = <0x02 0x11 0x02 0xc5>;
		dma-names = "tx", "rx";
		compatible = "rockchip,rk3308-uart", "snps,dw-apb-uart";
		status = "okay";
		reg = <0x00 0xff0a0000 0x00 0x100>;
		phandle = <0x90>;
		dmas = <0x14 0x04 0x14 0x05>;
		reg-shift = <0x02>;
	};

	i2s@ff360000 {
		clock-names = "i2s_clk", "i2s_hclk";
		resets = <0x02 0x97 0x02 0x96>;
		interrupts = <0x00 0x35 0x04>;
		clocks = <0x02 0x5e 0x02 0xa9>;
		dma-names = "rx";
		compatible = "rockchip,rk3308-i2s", "rockchip,rk3066-i2s";
		status = "disabled";
		reg = <0x00 0xff360000 0x00 0x1000>;
		phandle = <0xb3>;
		dmas = <0x1b 0x0b>;
		reset-names = "reset-m", "reset-h";
	};

	regulator-vcc-io {
		regulator-max-microvolt = <0x325aa0>;
		regulator-boot-on;
		regulator-always-on;
		regulator-min-microvolt = <0x325aa0>;
		regulator-name = "vcc_io";
		compatible = "regulator-fixed";
		phandle = <0x0c>;
		vin-supply = <0x82>;
	};

	spi@ff130000 {
		pinctrl-names = "default";
		#address-cells = <0x01>;
		pinctrl-0 = <0x27 0x28 0x29 0x2a>;
		clock-names = "spiclk", "apb_pclk";
		interrupts = <0x00 0x10 0x04>;
		clocks = <0x02 0x1c 0x02 0xd0>;
		#size-cells = <0x00>;
		dma-names = "tx", "rx";
		compatible = "rockchip,rk3308-spi", "rockchip,rk3066-spi";
		status = "disabled";
		reg = <0x00 0xff130000 0x00 0x1000>;
		phandle = <0x96>;
		dmas = <0x14 0x02 0x14 0x03>;
	};

	sound_i2s {
		simple-audio-card,bitclock-master = <0x11e>;
		simple-audio-card,name = "DAC";
		simple-audio-card,format = "i2s";
		compatible = "simple-audio-card";
		status = "okay";
		simple-audio-card,frame-master = <0x11e>;
		simple-audio-card,mclk-fs = <0x100>;

		simple-audio-card,cpu {
			phandle = <0x11e>;
			sound-dai = <0xaf>;
		};

		simple-audio-card,codec {
			phandle = <0x120>;
			sound-dai = <0x11f>;
		};
	};

	serial@ff0e0000 {
		reg-io-width = <0x04>;
		pinctrl-names = "default";
		pinctrl-0 = <0x1c 0x1d 0x1e>;
		clock-names = "baudclk", "apb_pclk";
		interrupts = <0x00 0x16 0x04>;
		clocks = <0x02 0x15 0x02 0xc9>;
		uart-has-rtscts;
		dma-names = "tx", "rx";
		compatible = "rockchip,rk3308-uart", "snps,dw-apb-uart";
		status = "okay";
		reg = <0x00 0xff0e0000 0x00 0x100>;
		phandle = <0x94>;
		dmas = <0x1b 0x12 0x1b 0x13>;
		reg-shift = <0x02>;

		bluetooth {
			device-wake-gpios = <0x1f 0x0a 0x00>;
			pinctrl-names = "default";
			pinctrl-0 = <0x20 0x21 0x22>;
			host-wake-gpios = <0x1f 0x0c 0x00>;
			compatible = "realtek,rtl8723ds-bt";
			enable-gpios = <0x1f 0x0b 0x00>;
		};
	};

	syscon@ff00c000 {
		#address-cells = <0x01>;
		#size-cells = <0x01>;
		compatible = "rockchip,rk3308-core-grf", "syscon", "simple-mfd";
		reg = <0x00 0xff00c000 0x00 0x1000>;
		phandle = <0x8a>;
	};

	leds {
		pinctrl-names = "default";
		pinctrl-0 = <0x7d 0x7e>;
		compatible = "gpio-leds";

		blue-led {
			linux,default-trigger = "heartbeat";
			function = "heartbeat";
			color = <0x03>;
			label = "rockpis:blue:user";
			default-state = "on";
			gpios = <0x60 0x05 0x00>;
		};

		green-led {
			linux,default-trigger = "default-on";
			function = "power";
			color = <0x02>;
			label = "rockpis:green:power";
			default-state = "on";
			gpios = <0x60 0x06 0x00>;
		};
	};

	psci {
		method = "smc";
		compatible = "arm,psci-1.0";
	};

	xin24m {
		clock-output-names = "xin24m";
		#clock-cells = <0x00>;
		clock-frequency = <0x16e3600>;
		compatible = "fixed-clock";
		phandle = <0x70>;
	};

	ethernet@ff4e0000 {
		pinctrl-names = "default";
		phy-supply = <0x0c>;
		phy-mode = "rmii";
		pinctrl-0 = <0x69 0x6a>;
		clock-names = "stmmaceth", "mac_clk_rx", "mac_clk_tx", "clk_mac_ref", "clk_mac_refout", "aclk_mac", "pclk_mac", "clk_mac_speed";
		local-mac-address = [da 1c b5 7a b9 78];
		resets = <0x02 0x7d>;
		interrupts = <0x00 0x40 0x04>;
		clocks = <0x02 0x40 0x02 0x42 0x02 0x42 0x02 0x41 0x02 0x40 0x02 0x86 0x02 0xc3 0x02 0x43>;
		clock_in_out = "output";
		compatible = "rockchip,rk3308-gmac";
		status = "okay";
		rockchip,grf = <0x3d>;
		interrupt-names = "macirq";
		reg = <0x00 0xff4e0000 0x00 0x10000>;
		phandle = <0xbd>;
		phy-handle = <0x6b>;
		reset-names = "stmmaceth";

		mdio {
			#address-cells = <0x01>;
			#size-cells = <0x00>;
			compatible = "snps,dwmac-mdio";

			ethernet-phy@1 {
				pinctrl-names = "default";
				reset-deassert-us = <0xc350>;
				pinctrl-0 = <0x6c>;
				reset-assert-us = <0x4e20>;
				reset-gpios = <0x60 0x07 0x01>;
				compatible = "ethernet-phy-ieee802.3-c22";
				reg = <0x01>;
				phandle = <0x6b>;
			};
		};
	};

	regulator-vcc5v0-otg {
		pinctrl-names = "default";
		gpio = <0x60 0x15 0x00>;
		pinctrl-0 = <0x83>;
		regulator-always-on;
		enable-active-high;
		regulator-name = "vcc5v0_otg";
		compatible = "regulator-fixed";
		phandle = <0x0f>;
		vin-supply = <0x82>;
	};

	i2c@ff060000 {
		pinctrl-names = "default";
		#address-cells = <0x01>;
		pinctrl-0 = <0x12>;
		clock-names = "i2c", "pclk";
		interrupts = <0x00 0x0d 0x04>;
		clocks = <0x02 0x18 0x02 0xcc>;
		#size-cells = <0x00>;
		compatible = "rockchip,rk3308-i2c", "rockchip,rk3399-i2c";
		status = "disabled";
		reg = <0x00 0xff060000 0x00 0x1000>;
		phandle = <0x8d>;
	};

	dma-controller@ff2d0000 {
		clock-names = "apb_pclk";
		interrupts = <0x00 0x02 0x04 0x00 0x03 0x04>;
		clocks = <0x02 0x8b>;
		arm,pl330-periph-burst;
		compatible = "arm,pl330", "arm,primecell";
		reg = <0x00 0xff2d0000 0x00 0x4000>;
		phandle = <0x1b>;
		#dma-cells = <0x01>;
	};

	watchdog@ff080000 {
		interrupts = <0x00 0x0a 0x04>;
		clocks = <0x02 0xd6>;
		compatible = "rockchip,rk3308-wdt", "snps,dw-wdt";
		status = "okay";
		reg = <0x00 0xff080000 0x00 0x100>;
		phandle = <0x8f>;
	};

	grf@ff000000 {
		compatible = "rockchip,rk3308-grf", "syscon", "simple-mfd";
		reg = <0x00 0xff000000 0x00 0x8000>;
		phandle = <0x3d>;

		reboot-mode {
			mode-normal = <0x5242c300>;
			mode-loader = <0x5242c301>;
			mode-bootloader = <0x5242c301>;
			mode-recovery = <0x5242c303>;
			mode-fastboot = <0x5242c309>;
			offset = <0x500>;
			compatible = "syscon-reboot-mode";
		};

		io-domains {
			vccio0-supply = <0x0c>;
			vccio1-supply = <0x0c>;
			vccio2-supply = <0x0c>;
			vccio3-supply = <0x0c>;
			vccio4-supply = <0x0d>;
			vccio5-supply = <0x0c>;
			compatible = "rockchip,rk3308-io-voltage-domain";
			status = "okay";
			phandle = <0x88>;
		};
	};

	pwm@ff160030 {
		pinctrl-names = "default";
		pinctrl-0 = <0x32>;
		clock-names = "pwm", "pclk";
		clocks = <0x02 0x79 0x02 0xe8>;
		#pwm-cells = <0x03>;
		compatible = "rockchip,rk3308-pwm", "rockchip,rk3328-pwm";
		status = "disabled";
		reg = <0x00 0xff160030 0x00 0x10>;
		phandle = <0x9b>;
	};

	pwm@ff160020 {
		pinctrl-names = "default";
		pinctrl-0 = <0x31>;
		clock-names = "pwm", "pclk";
		clocks = <0x02 0x79 0x02 0xe8>;
		#pwm-cells = <0x03>;
		compatible = "rockchip,rk3308-pwm", "rockchip,rk3328-pwm";
		status = "disabled";
		reg = <0x00 0xff160020 0x00 0x10>;
		phandle = <0x9a>;
	};

	pwm@ff160010 {
		pinctrl-names = "default";
		pinctrl-0 = <0x30>;
		clock-names = "pwm", "pclk";
		clocks = <0x02 0x79 0x02 0xe8>;
		#pwm-cells = <0x03>;
		compatible = "rockchip,rk3308-pwm", "rockchip,rk3328-pwm";
		status = "disabled";
		reg = <0x00 0xff160010 0x00 0x10>;
		phandle = <0x99>;
	};

	sram@fff80000 {
		#address-cells = <0x01>;
		#size-cells = <0x01>;
		compatible = "mmio-sram";
		ranges = <0x00 0x00 0xfff80000 0x40000>;
		reg = <0x00 0xfff80000 0x00 0x40000>;
		phandle = <0xbf>;

		ddr-sram@0 {
			reg = <0x00 0x8000>;
		};

		vad-sram@8000 {
			reg = <0x8000 0x38000>;
			phandle = <0xc0>;
		};
	};

	mmc@ff4a0000 {
		fifo-depth = <0x100>;
		pinctrl-names = "default";
		#address-cells = <0x01>;
		pinctrl-0 = <0x5c 0x5d 0x5e>;
		clock-names = "biu", "ciu", "ciu-drive", "ciu-sample";
		cap-sd-highspeed;
		vqmmc-supply = <0x0d>;
		no-mmc;
		bus-width = <0x04>;
		non-removable;
		cap-sdio-irq;
		interrupts = <0x00 0x4e 0x04>;
		clocks = <0x02 0x9b 0x02 0x35 0x02 0x36 0x02 0x37>;
		#size-cells = <0x00>;
		vmmc-supply = <0x0c>;
		keep-power-in-suspend;
		no-sd;
		compatible = "rockchip,rk3308-dw-mshc", "rockchip,rk3288-dw-mshc";
		status = "okay";
		mmc-pwrseq = <0x5f>;
		reg = <0x00 0xff4a0000 0x00 0x4000>;
		phandle = <0xba>;
		max-frequency = <0x5f5e100>;
		sd-uhs-sdr50;

		wifi@1 {
			pinctrl-names = "default";
			pinctrl-0 = <0x61>;
			interrupts = <0x00 0x04>;
			interrupt-parent = <0x60>;
			interrupt-names = "host-wake";
			reg = <0x01>;
			phandle = <0xbb>;
		};
	};

	i2s@ff330000 {
		clock-names = "mclk_tx", "mclk_rx", "hclk";
		resets = <0x02 0x92 0x02 0x93>;
		interrupts = <0x00 0x33 0x04>;
		clocks = <0x02 0x58 0x02 0x5a 0x02 0xa7>;
		dma-names = "rx";
		compatible = "rockchip,rk3308-i2s-tdm";
		status = "disabled";
		rockchip,grf = <0x3d>;
		reg = <0x00 0xff330000 0x00 0x1000>;
		phandle = <0xb1>;
		dmas = <0x1b 0x07>;
		reset-names = "tx-m", "rx-m";
	};

	pwm@ff160000 {
		pinctrl-names = "default";
		pinctrl-0 = <0x2f>;
		clock-names = "pwm", "pclk";
		clocks = <0x02 0x79 0x02 0xe8>;
		#pwm-cells = <0x03>;
		compatible = "rockchip,rk3308-pwm", "rockchip,rk3328-pwm";
		status = "disabled";
		reg = <0x00 0xff160000 0x00 0x10>;
		phandle = <0x98>;
	};

	usb@ff400000 {
		g-np-tx-fifo-size = <0x10>;
		phy-names = "usb2-phy";
		clock-names = "otg";
		g-tx-fifo-size = <0x100 0x80 0x80 0x40 0x20 0x10>;
		interrupts = <0x00 0x42 0x04>;
		clocks = <0x02 0x9e>;
		g-rx-fifo-size = <0x118>;
		compatible = "rockchip,rk3308-usb", "rockchip,rk3066-usb", "snps,dwc2";
		status = "okay";
		phys = <0x53>;
		reg = <0x00 0xff400000 0x00 0x40000>;
		phandle = <0xb5>;
		dr_mode = "peripheral";
	};

	interrupt-controller@ff580000 {
		#address-cells = <0x00>;
		interrupts = <0x01 0x09 0x04>;
		compatible = "arm,gic-400";
		#interrupt-cells = <0x03>;
		reg = <0x00 0xff581000 0x00 0x1000 0x00 0xff582000 0x00 0x2000 0x00 0xff584000 0x00 0x2000 0x00 0xff586000 0x00 0x2000>;
		phandle = <0x01>;
		interrupt-controller;
	};

	serial@ff0b0000 {
		reg-io-width = <0x04>;
		pinctrl-names = "default";
		pinctrl-0 = <0x16 0x17 0x18>;
		clock-names = "baudclk", "apb_pclk";
		interrupts = <0x00 0x13 0x04>;
		clocks = <0x02 0x12 0x02 0xc6>;
		dma-names = "tx", "rx";
		compatible = "rockchip,rk3308-uart", "snps,dw-apb-uart";
		status = "disabled";
		reg = <0x00 0xff0b0000 0x00 0x100>;
		phandle = <0x91>;
		dmas = <0x14 0x06 0x14 0x07>;
		reg-shift = <0x02>;
	};

	timer {
		interrupts = <0x01 0x0d 0xf04 0x01 0x0e 0xf04 0x01 0x0b 0xf04 0x01 0x0a 0xf04>;
		compatible = "arm,armv8-timer";
	};

	opp-table-0 {
		opp-shared;
		compatible = "operating-points-v2";
		phandle = <0x03>;

		opp-1008000000 {
			opp-microvolt = <0x112a88 0x112a88 0x147260>;
			opp-hz = <0x00 0x3c14dc00>;
			clock-latency-ns = <0x9c40>;
		};

		opp-816000000 {
			opp-microvolt = <0xfa3e8 0xfa3e8 0x147260>;
			opp-hz = <0x00 0x30a32c00>;
			clock-latency-ns = <0x9c40>;
		};

		opp-600000000 {
			opp-microvolt = <0xe7ef0 0xe7ef0 0x147260>;
			opp-hz = <0x00 0x23c34600>;
			clock-latency-ns = <0x9c40>;
		};

		opp-408000000 {
			opp-microvolt = <0xe7ef0 0xe7ef0 0x147260>;
			opp-hz = <0x00 0x18519600>;
			opp-suspend;
			clock-latency-ns = <0x9c40>;
		};
	};

	spi@ff140000 {
		pinctrl-names = "default";
		#address-cells = <0x01>;
		pinctrl-0 = <0x2b 0x2c 0x2d 0x2e>;
		clock-names = "spiclk", "apb_pclk";
		interrupts = <0x00 0x11 0x04>;
		clocks = <0x02 0x1d 0x02 0xd1>;
		#size-cells = <0x00>;
		dma-names = "tx", "rx";
		compatible = "rockchip,rk3308-spi", "rockchip,rk3066-spi";
		status = "disabled";
		reg = <0x00 0xff140000 0x00 0x1000>;
		phandle = <0x97>;
		dmas = <0x1b 0x10 0x1b 0x11>;
	};

	regulator-vdd-core {
		regulator-max-microvolt = <0x147260>;
		regulator-boot-on;
		regulator-always-on;
		regulator-min-microvolt = <0xc9e78>;
		regulator-name = "vdd_core";
		compatible = "pwm-regulator";
		regulator-settling-time-up-us = <0xfa>;
		phandle = <0x06>;
		pwms = <0x84 0x00 0x1388 0x01>;
		pwm-supply = <0x82>;
	};

	sdio-pwrseq {
		pinctrl-names = "default";
		pinctrl-0 = <0x81>;
		reset-gpios = <0x60 0x02 0x01>;
		compatible = "mmc-pwrseq-simple";
		phandle = <0x5f>;
	};

	usb@ff440000 {
		phy-names = "usb";
		interrupts = <0x00 0x47 0x04>;
		clocks = <0x02 0x9f 0x02 0xa0 0x0e>;
		compatible = "generic-ehci";
		status = "okay";
		phys = <0x54>;
		reg = <0x00 0xff440000 0x00 0x10000>;
		phandle = <0xb6>;
	};

	vop@ff2e0000 {
		pinctrl-names = "default";
		pinctrl-0 = <0x40>;
		clock-names = "aclk_vop", "dclk_vop", "hclk_vop";
		resets = <0x02 0x26 0x02 0x27 0x02 0x28>;
		interrupts = <0x00 0x2e 0x04>;
		clocks = <0x02 0x88 0x02 0x7d 0x02 0xac>;
		compatible = "rockchip,rk3308-vop";
		status = "disabled";
		reg = <0x00 0xff2e0000 0x00 0x1fc>;
		phandle = <0xae>;
		reset-names = "axi", "ahb", "dclk";

		port {
			#address-cells = <0x01>;
			#size-cells = <0x00>;
			phandle = <0x0b>;
		};
	};

	aliases {
		i2c3 = "/i2c@ff070000";
		ethernet0 = "/ethernet@ff4e0000";
		spi2 = "/spi@ff140000";
		gpio0 = "/pinctrl/gpio@ff220000";
		i2c1 = "/i2c@ff050000";
		spi0 = "/spi@ff120000";
		mmc1 = "/mmc@ff480000";
		serial3 = "/serial@ff0d0000";
		serial1 = "/serial@ff0b0000";
		gpio3 = "/pinctrl/gpio@ff250000";
		gpio1 = "/pinctrl/gpio@ff230000";
		i2c2 = "/i2c@ff060000";
		spi1 = "/spi@ff130000";
		i2c0 = "/i2c@ff040000";
		mmc2 = "/mmc@ff4a0000";
		serial4 = "/serial@ff0e0000";
		mmc0 = "/mmc@ff490000";
		serial2 = "/serial@ff0c0000";
		gpio4 = "/pinctrl/gpio@ff260000";
		serial0 = "/serial@ff0a0000";
		gpio2 = "/pinctrl/gpio@ff240000";
	};

	rktimer@ff1a0000 {
		clock-names = "pclk", "timer";
		interrupts = <0x00 0x19 0x04>;
		clocks = <0x02 0xd4 0x02 0x1e>;
		compatible = "rockchip,rk3288-timer";
		reg = <0x00 0xff1a0000 0x00 0x20>;
		phandle = <0xa3>;
	};

	i2c@ff070000 {
		pinctrl-names = "default";
		#address-cells = <0x01>;
		pinctrl-0 = <0x13>;
		clock-names = "i2c", "pclk";
		interrupts = <0x00 0x0e 0x04>;
		clocks = <0x02 0x19 0x02 0xcd>;
		#size-cells = <0x00>;
		compatible = "rockchip,rk3308-i2c", "rockchip,rk3399-i2c";
		status = "disabled";
		reg = <0x00 0xff070000 0x00 0x1000>;
		phandle = <0x8e>;
	};

	regulator-vcc5v0-sys {
		regulator-max-microvolt = <0x4c4b40>;
		regulator-boot-on;
		regulator-always-on;
		regulator-min-microvolt = <0x4c4b40>;
		regulator-name = "vcc5v0_sys";
		compatible = "regulator-fixed";
		phandle = <0x82>;
	};

	nand-controller@ff4b0000 {
		pinctrl-names = "default";
		pinctrl-0 = <0x62 0x63 0x64 0x65 0x66 0x67 0x68>;
		clock-names = "ahb", "nfc";
		assigned-clocks = <0x02 0x2d>;
		assigned-clock-rates = <0x8f0d180>;
		interrupts = <0x00 0x51 0x04>;
		clocks = <0x02 0x99 0x02 0x2d>;
		compatible = "rockchip,rk3308-nfc", "rockchip,rv1108-nfc";
		status = "disabled";
		reg = <0x00 0xff4b0000 0x00 0x4000>;
		phandle = <0xbc>;
	};

	clock-controller@ff500000 {
		#reset-cells = <0x01>;
		clock-names = "xin24m";
		assigned-clocks = <0x02 0x0f>;
		assigned-clock-rates = <0x8000>;
		clocks = <0x70>;
		#clock-cells = <0x01>;
		compatible = "rockchip,rk3308-cru";
		rockchip,grf = <0x3d>;
		reg = <0x00 0xff500000 0x00 0x1000>;
		phandle = <0x02>;
	};

	syscon@ff00b000 {
		#address-cells = <0x01>;
		#size-cells = <0x01>;
		compatible = "rockchip,rk3308-detect-grf", "syscon", "simple-mfd";
		reg = <0x00 0xff00b000 0x00 0x1000>;
		phandle = <0x71>;
	};

	pwm@ff170030 {
		pinctrl-names = "default";
		pinctrl-0 = <0x36>;
		clock-names = "pwm", "pclk";
		clocks = <0x02 0x78 0x02 0xe7>;
		#pwm-cells = <0x03>;
		compatible = "rockchip,rk3308-pwm", "rockchip,rk3328-pwm";
		status = "disabled";
		reg = <0x00 0xff170030 0x00 0x10>;
		phandle = <0x9f>;
	};

	chosen {
		u-boot,version = "2026.07_armbian-2026.07-Sece3-P4834-Hadda-Vb7b8-B5da4-R448a";
		linux,initrd-end = <0x00 0x1cbff31a>;
		bootargs = "root=UUID=042556cc-28a6-4c97-820c-a7da6b682d6d rootwait rootfstype=ext4 splash=verbose console=ttyS0,1500000  consoleblank=0 loglevel=1 ubootpart=97b588c7-01 usb-storage.quirks=0x2537:0x1066:u,0x2537:0x1068:u cma=16M  cgroup_enable=cpuset cgroup_memory=1 cgroup_enable=memory";
		smbios3-entrypoint = <0x00 0x1df56000>;
		kaslr-seed = <0x00 0x00>;
		linux,initrd-start = <0x00 0x1b51e000>;
		stdout-path = "serial0:1500000n8";
	};

	pwm@ff170020 {
		pinctrl-names = "default";
		pinctrl-0 = <0x35>;
		clock-names = "pwm", "pclk";
		clocks = <0x02 0x78 0x02 0xe7>;
		#pwm-cells = <0x03>;
		compatible = "rockchip,rk3308-pwm", "rockchip,rk3328-pwm";
		status = "disabled";
		reg = <0x00 0xff170020 0x00 0x10>;
		phandle = <0x9e>;
	};

	i2s@ff300000 {
		rockchip,always-on;
		pinctrl-names = "default";
		rockchip,cru = <0x02>;
		pinctrl-0 = <0x41 0x42 0x43 0x44 0x45 0x46 0x47 0x48 0x49 0x4a 0x4b 0x4c 0x4d>;
		clock-names = "mclk_tx", "mclk_rx", "hclk", "mclk_tx_src", "mclk_rx_src", "mclk_root0", "mclk_root1";
		resets = <0x02 0x89 0x02 0x8a>;
		interrupts = <0x00 0x30 0x04>;
		clocks = <0x02 0x4c 0x02 0x4e 0x02 0xa4 0x02 0x6e 0x02 0x6f 0x02 0x03 0x02 0x04>;
		rockchip,mclk-calibrate;
		dma-names = "tx", "rx";
		#sound-dai-cells = <0x00>;
		compatible = "rockchip,rk3308-i2s-tdm";
		status = "okay";
		rockchip,grf = <0x3d>;
		reg = <0x00 0xff300000 0x00 0x1000>;
		phandle = <0xaf>;
		dmas = <0x1b 0x00 0x1b 0x01>;
		reset-names = "tx-m", "rx-m";
	};

	efuse@ff210000 {
		#address-cells = <0x01>;
		clock-names = "otp", "apb_pclk", "phy";
		resets = <0x02 0x54>;
		clocks = <0x02 0x27 0x02 0xd5 0x02 0xe5>;
		#size-cells = <0x01>;
		compatible = "rockchip,rk3308-otp";
		reg = <0x00 0xff210000 0x00 0x4000>;
		phandle = <0xa5>;
		reset-names = "phy";

		logic-leakage@18 {
			reg = <0x18 0x01>;
			phandle = <0xa8>;
		};

		id@7 {
			reg = <0x07 0x10>;
			phandle = <0xa6>;
		};

		cpu-leakage@17 {
			reg = <0x17 0x01>;
			phandle = <0xa7>;
		};
	};

	pwm@ff170010 {
		pinctrl-names = "default";
		pinctrl-0 = <0x34>;
		clock-names = "pwm", "pclk";
		clocks = <0x02 0x78 0x02 0xe7>;
		#pwm-cells = <0x03>;
		compatible = "rockchip,rk3308-pwm", "rockchip,rk3328-pwm";
		status = "disabled";
		reg = <0x00 0xff170010 0x00 0x10>;
		phandle = <0x9d>;
	};

	syscon@ff008000 {
		#address-cells = <0x01>;
		#size-cells = <0x01>;
		compatible = "rockchip,rk3308-usb2phy-grf", "syscon", "simple-mfd";
		reg = <0x00 0xff008000 0x00 0x4000>;
		phandle = <0x89>;

		usb2phy@100 {
			clock-output-names = "usb480m_phy";
			clock-names = "phyclk";
			assigned-clocks = <0x02 0x0e>;
			assigned-clock-parents = <0x0e>;
			clocks = <0x02 0x48>;
			#clock-cells = <0x00>;
			compatible = "rockchip,rk3308-usb2phy";
			status = "okay";
			reg = <0x100 0x10>;
			phandle = <0x0e>;

			host-port {
				phy-supply = <0x0f>;
				interrupts = <0x00 0x4a 0x04>;
				#phy-cells = <0x00>;
				status = "okay";
				interrupt-names = "linestate";
				phandle = <0x54>;
			};

			otg-port {
				phy-supply = <0x0f>;
				interrupts = <0x00 0x43 0x04 0x00 0x44 0x04 0x00 0x45 0x04>;
				#phy-cells = <0x00>;
				status = "okay";
				interrupt-names = "otg-bvalid", "otg-id", "linestate";
				phandle = <0x53>;
			};
		};
	};

	pwm@ff170000 {
		pinctrl-names = "default";
		pinctrl-0 = <0x33>;
		clock-names = "pwm", "pclk";
		clocks = <0x02 0x78 0x02 0xe7>;
		#pwm-cells = <0x03>;
		compatible = "rockchip,rk3308-pwm", "rockchip,rk3328-pwm";
		status = "disabled";
		reg = <0x00 0xff170000 0x00 0x10>;
		phandle = <0x9c>;
	};

	serial@ff0c0000 {
		reg-io-width = <0x04>;
		pinctrl-names = "default";
		pinctrl-0 = <0x19>;
		clock-names = "baudclk", "apb_pclk";
		interrupts = <0x00 0x14 0x04>;
		clocks = <0x02 0x13 0x02 0xc7>;
		dma-names = "tx", "rx";
		compatible = "rockchip,rk3308-uart", "snps,dw-apb-uart";
		status = "disabled";
		reg = <0x00 0xff0c0000 0x00 0x100>;
		phandle = <0x92>;
		dmas = <0x14 0x08 0x14 0x09>;
		reg-shift = <0x02>;
	};

	cpus {
		#address-cells = <0x02>;
		#size-cells = <0x00>;

		cpu@1 {
			cpu-idle-states = <0x04>;
			device_type = "cpu";
			compatible = "arm,cortex-a35";
			next-level-cache = <0x05>;
			reg = <0x00 0x01>;
			enable-method = "psci";
			phandle = <0x08>;
			operating-points-v2 = <0x03>;
		};

		l2-cache {
			cache-level = <0x02>;
			cache-unified;
			compatible = "cache";
			phandle = <0x05>;
		};

		idle-states {
			entry-method = "psci";

			cpu-sleep {
				entry-latency-us = <0x78>;
				local-timer-stop;
				exit-latency-us = <0xfa>;
				arm,psci-suspend-param = <0x10000>;
				compatible = "arm,idle-state";
				phandle = <0x04>;
				min-residency-us = <0x384>;
			};
		};

		cpu@2 {
			cpu-idle-states = <0x04>;
			device_type = "cpu";
			compatible = "arm,cortex-a35";
			next-level-cache = <0x05>;
			reg = <0x00 0x02>;
			enable-method = "psci";
			phandle = <0x09>;
			operating-points-v2 = <0x03>;
		};

		cpu@0 {
			cpu-supply = <0x06>;
			clocks = <0x02 0x05>;
			cpu-idle-states = <0x04>;
			device_type = "cpu";
			compatible = "arm,cortex-a35";
			dynamic-power-coefficient = <0x5a>;
			next-level-cache = <0x05>;
			reg = <0x00 0x00>;
			enable-method = "psci";
			phandle = <0x07>;
			operating-points-v2 = <0x03>;
			#cooling-cells = <0x02>;
		};

		cpu@3 {
			cpu-idle-states = <0x04>;
			device_type = "cpu";
			compatible = "arm,cortex-a35";
			next-level-cache = <0x05>;
			reg = <0x00 0x03>;
			enable-method = "psci";
			phandle = <0x0a>;
			operating-points-v2 = <0x03>;
		};
	};

	__symbols__ {
		i2c3 = "/i2c@ff070000";
		pwm9 = "/pwm@ff160010";
		pdm_m2_clkm = "/pinctrl/pdm_m2/pdm-m2-clkm";
		rtc_32k = "/pinctrl/rtc/rtc-32k";
		i2s_2ch_1 = "/i2s@ff360000";
		i2s_8ch_0_sclkrx = "/pinctrl/i2s_8ch_0/i2s-8ch-0-sclkrx";
		sdmmc_clk = "/pinctrl/sdmmc/sdmmc-clk";
		i2s_8ch_2 = "/i2s@ff320000";
		macm1_refclk_12ma = "/pinctrl/gmac-m1/macm1-refclk-12ma";
		pcfg_pull_none_4ma = "/pinctrl/pcfg-pull-none-4ma";
		pwm10_pin_pull_down = "/pinctrl/pwm10/pwm10-pin-pull-down";
		flash_cle = "/pinctrl/flash/flash-cle";
		thermal_zones = "/thermal-zones";
		spi1_miso = "/pinctrl/spi1/spi1-miso";
		pcfg_input_high = "/pinctrl/pcfg-input-high";
		emmc_rstn = "/pinctrl/emmc/emmc-rstn";
		spi1m1_csn0 = "/pinctrl/spi1-m1/spi1m1-csn0";
		spi2_csn0 = "/pinctrl/spi2/spi2-csn0";
		pwm7_pin_pull_down = "/pinctrl/pwm7/pwm7-pin-pull-down";
		pcfg_pull_none_smt = "/pinctrl/pcfg-pull-none-smt";
		spdif_out = "/pinctrl/spdif_out/spdif-out";
		pdm_m0_clk = "/pinctrl/pdm_m0/pdm-m0-clk";
		pdm_m1_sdi2 = "/pinctrl/pdm_m1/pdm-m1-sdi2";
		spi2 = "/spi@ff140000";
		lcdc_rgb888_m1 = "/pinctrl/lcdc/lcdc-rgb888-m1";
		gpio0 = "/pinctrl/gpio@ff220000";
		saradc = "/saradc@ff1e0000";
		pinctrl = "/pinctrl";
		flash_wrn = "/pinctrl/flash/flash-wrn";
		green_led = "/pinctrl/leds/green-led";
		uart2m1_xfer = "/pinctrl/uart2-m1/uart2m1-xfer";
		i2c1 = "/i2c@ff050000";
		sdio_intn = "/pinctrl/sdio/sdio-intn";
		u2phy_otg = "/syscon@ff008000/usb2phy@100/otg-port";
		pwm7 = "/pwm@ff170030";
		gmac = "/ethernet@ff4e0000";
		i2s_8ch_0 = "/i2s@ff300000";
		emmc_cmd = "/pinctrl/emmc/emmc-cmd";
		pcfg_pull_none = "/pinctrl/pcfg-pull-none";
		rtl8723ds = "/mmc@ff4a0000/wifi@1";
		target = "/thermal-zones/soc-thermal/trips/trip-point-1";
		uart3m1_xfer = "/pinctrl/uart3-m1/uart3m1-xfer";
		sdmmc_bus1 = "/pinctrl/sdmmc/sdmmc-bus1";
		pdm_m1_sdi0 = "/pinctrl/pdm_m1/pdm-m1-sdi0";
		spi0 = "/spi@ff120000";
		pwm0_pin = "/pinctrl/pwm0/pwm0-pin";
		i2c3m2_xfer = "/pinctrl/i2c3-m2/i2c3m2-xfer";
		pwm5_pin_pull_down = "/pinctrl/pwm5/pwm5-pin-pull-down";
		sfc_cs0 = "/pinctrl/sfc/sfc-cs0";
		spi0_miso = "/pinctrl/spi0/spi0-miso";
		pwm4_pin = "/pinctrl/pwm4/pwm4-pin";
		usb_host_ohci = "/usb@ff450000";
		rmii_pins = "/pinctrl/gmac/rmii-pins";
		pwm5 = "/pwm@ff170010";
		i2s_8ch_1_m0_sdo1_sdi3 = "/pinctrl/i2s_8ch_1_m0/i2s-8ch-1-m0-sdo1-sdi3";
		spi1_csn0 = "/pinctrl/spi1/spi1-csn0";
		logic_leakage = "/efuse@ff210000/logic-leakage@18";
		pdm_m0_sdi2 = "/pinctrl/pdm_m0/pdm-m0-sdi2";
		pwm10 = "/pwm@ff160020";
		i2s_8ch_1_m1_sdo0 = "/pinctrl/i2s_8ch_1_m1/i2s-8ch-1-m1-sdo0";
		rktimer = "/rktimer@ff1a0000";
		i2s_8ch_0_sdo2 = "/pinctrl/i2s_8ch_0/i2s-8ch-0-sdo2";
		pwm8_pin = "/pinctrl/pwm8/pwm8-pin";
		spi2_clk = "/pinctrl/spi2/spi2-clk";
		pcfg_input = "/pinctrl/pcfg-input";
		uart4 = "/serial@ff0e0000";
		uart2m0_xfer = "/pinctrl/uart2-m0/uart2m0-xfer";
		vcc5v0_otg = "/regulator-vcc5v0-otg";
		cpu0_opp_table = "/opp-table-0";
		i2s_2ch_0_sclk = "/pinctrl/i2s_2ch_0/i2s-2ch-0-sclk";
		pwm3 = "/pwm@ff180030";
		pwm3_pin_pull_down = "/pinctrl/pwm3/pwm3-pin-pull-down";
		i2s_8ch_1_m0_lrcktx = "/pinctrl/i2s_8ch_1_m0/i2s-8ch-1-m0-lrcktx";
		i2s0_out = "/i2s0-out";
		pdm_m0_sdi0 = "/pinctrl/pdm_m0/pdm-m0-sdi0";
		emmc_clk = "/pinctrl/emmc/emmc-clk";
		cru = "/clock-controller@ff500000";
		sfc_bus4 = "/pinctrl/sfc/sfc-bus4";
		pdm_m1_clk = "/pinctrl/pdm_m1/pdm-m1-clk";
		i2s_8ch_0_sdo0 = "/pinctrl/i2s_8ch_0/i2s-8ch-0-sdo0";
		i2c3m1_xfer = "/pinctrl/i2c3-m1/i2c3m1-xfer";
		uart4_xfer = "/pinctrl/uart4/uart4-xfer";
		cpu3 = "/cpus/cpu@3";
		flash_bus8 = "/pinctrl/flash/flash-bus8";
		nfc = "/nand-controller@ff4b0000";
		uart2 = "/serial@ff0c0000";
		host_wake_bt = "/pinctrl/bluetooth/host-wake-bt";
		spi1m1_mosi = "/pinctrl/spi1-m1/spi1m1-mosi";
		dmac0 = "/dma-controller@ff2c0000";
		pcfg_pull_up_12ma = "/pinctrl/pcfg-pull-up-12ma";
		spi2_mosi = "/pinctrl/spi2/spi2-mosi";
		u2phy = "/syscon@ff008000/usb2phy@100";
		pcfg_output_low = "/pinctrl/pcfg-output-low";
		sdio_pwrseq = "/sdio-pwrseq";
		mac_refclk_12ma = "/pinctrl/gmac/mac-refclk-12ma";
		pdm_m2_sdi3 = "/pinctrl/pdm_m2/pdm-m2-sdi3";
		otp = "/efuse@ff210000";
		i2s_8ch_1_m1_lrcktx = "/pinctrl/i2s_8ch_1_m1/i2s-8ch-1-m1-lrcktx";
		i2s_8ch_1_m0_lrckrx = "/pinctrl/i2s_8ch_1_m0/i2s-8ch-1-m0-lrckrx";
		spi0_csn0 = "/pinctrl/spi0/spi0-csn0";
		gic = "/interrupt-controller@ff580000";
		i2s_8ch_1_m0_sdo0 = "/pinctrl/i2s_8ch_1_m0/i2s-8ch-1-m0-sdo0";
		sdmmc_det = "/pinctrl/sdmmc/sdmmc-det";
		i2s_8ch_1_m1_sdi0 = "/pinctrl/i2s_8ch_1_m1/i2s-8ch-1-m1-sdi0";
		i2s_8ch_1_m1_sdo3_sdi1 = "/pinctrl/i2s_8ch_1_m1/i2s-8ch-1-m1-sdo3_sdi1";
		rtl8201f = "/ethernet@ff4e0000/mdio/ethernet-phy@1";
		i2s_8ch_0_sdi2 = "/pinctrl/i2s_8ch_0/i2s-8ch-0-sdi2";
		uart0_rts_pin = "/pinctrl/uart0/uart0-rts-pin";
		pwm1 = "/pwm@ff180010";
		cpu_id = "/efuse@ff210000/id@7";
		threshold = "/thermal-zones/soc-thermal/trips/trip-point-0";
		sdio_bus1 = "/pinctrl/sdio/sdio-bus1";
		emmc_bus1 = "/pinctrl/emmc/emmc-bus1";
		tsadc_otp_out = "/pinctrl/tsadc/tsadc-otp-out";
		macm1_refclk = "/pinctrl/gmac-m1/macm1-refclk";
		xin24m = "/xin24m";
		sfc_bus2 = "/pinctrl/sfc/sfc-bus2";
		pcfg_pull_up_2ma = "/pinctrl/pcfg-pull-up-2ma";
		i2s_8ch_1_m1_lrckrx = "/pinctrl/i2s_8ch_1_m1/i2s-8ch-1-m1-lrckrx";
		spi1m1_clk = "/pinctrl/spi1-m1/spi1m1-clk";
		tsadc = "/tsadc@ff1f0000";
		i2s_2ch_0_lrck = "/pinctrl/i2s_2ch_0/i2s-2ch-0-lrck";
		uart0_cts = "/pinctrl/uart0/uart0-cts";
		gpio3 = "/pinctrl/gpio@ff250000";
		pwm1_pin = "/pinctrl/pwm1/pwm1-pin";
		pcfg_output_high = "/pinctrl/pcfg-output-high";
		cpu1 = "/cpus/cpu@1";
		uart0 = "/serial@ff0a0000";
		pwm1_pin_pull_down = "/pinctrl/pwm1/pwm1-pin-pull-down";
		i2s_8ch_1_m0_sclktx = "/pinctrl/i2s_8ch_1_m0/i2s-8ch-1-m0-sclktx";
		i2c2_xfer = "/pinctrl/i2c2/i2c2-xfer";
		l2 = "/cpus/l2-cache";
		pdm_m2_sdi1 = "/pinctrl/pdm_m2/pdm-m2-sdi1";
		uart4_cts = "/pinctrl/uart4/uart4-cts";
		pwm5_pin = "/pinctrl/pwm5/pwm5-pin";
		pwm11_pin_pull_down = "/pinctrl/pwm11/pwm11-pin-pull-down";
		emmc = "/mmc@ff490000";
		i2s_2ch_0_sdo = "/pinctrl/i2s_2ch_0/i2s-2ch-0-sdo";
		i2s_8ch_3 = "/i2s@ff330000";
		core_grf = "/syscon@ff00c000";
		i2c3m0_xfer = "/pinctrl/i2c3-m0/i2c3m0-xfer";
		uart3_xfer = "/pinctrl/uart3/uart3-xfer";
		usb2phy_grf = "/syscon@ff008000";
		i2s_8ch_1_m1_sclktx = "/pinctrl/i2s_8ch_1_m1/i2s-8ch-1-m1-sclktx";
		i2s_8ch_0_sdi0 = "/pinctrl/i2s_8ch_0/i2s-8ch-0-sdi0";
		pwm9_pin = "/pinctrl/pwm9/pwm9-pin";
		pwm8_pin_pull_down = "/pinctrl/pwm8/pwm8-pin-pull-down";
		spdif_in = "/pinctrl/spdif_in/spdif-in";
		i2s_8ch_1_m0_sclkrx = "/pinctrl/i2s_8ch_1_m0/i2s-8ch-1-m0-sclkrx";
		mac_clkin = "/external-mac-clock";
		rng = "/rng@ff2f0000";
		wifi_enable_h = "/pinctrl/sdio-pwrseq/wifi-enable-h";
		spi1_mosi = "/pinctrl/spi1/spi1-mosi";
		sdmmc_bus4 = "/pinctrl/sdmmc/sdmmc-bus4";
		cpu_leakage = "/efuse@ff210000/cpu-leakage@17";
		pdm_m1_sdi3 = "/pinctrl/pdm_m1/pdm-m1-sdi3";
		gpio1 = "/pinctrl/gpio@ff230000";
		vcc5v0_sys = "/regulator-vcc5v0-sys";
		wdt = "/watchdog@ff080000";
		i2s_8ch_1_m0_sdi0 = "/pinctrl/i2s_8ch_1_m0/i2s-8ch-1-m0-sdi0";
		i2s_8ch_1_m1_sclkrx = "/pinctrl/i2s_8ch_1_m1/i2s-8ch-1-m1-sclkrx";
		otg_vbus_drv = "/pinctrl/usb/otg-vbus-drv";
		spdif_tx = "/spdif-tx@ff3a0000";
		i2c2 = "/i2c@ff060000";
		sram = "/sram@fff80000";
		pwm8 = "/pwm@ff160000";
		emmc_bus8 = "/pinctrl/emmc/emmc-bus8";
		flash_rdn = "/pinctrl/flash/flash-rdn";
		i2s_2ch_0 = "/i2s@ff350000";
		i2s_8ch_1 = "/i2s@ff310000";
		sdio_cmd = "/pinctrl/sdio/sdio-cmd";
		pdm_m2_clk = "/pinctrl/pdm_m2/pdm-m2-clk";
		vcc_io = "/regulator-vcc-io";
		i2s_2ch_0_mclk = "/pinctrl/i2s_2ch_0/i2s-2ch-0-mclk";
		pcfg_pull_up_8ma = "/pinctrl/pcfg-pull-up-8ma";
		i2c1_xfer = "/pinctrl/i2c1/i2c1-xfer";
		i2s_8ch_1_m0_sdo2_sdi2 = "/pinctrl/i2s_8ch_1_m0/i2s-8ch-1-m0-sdo2-sdi2";
		vdd_log = "/regulator-vdd-log";
		pcfg_pull_down_4ma = "/pinctrl/pcfg-pull-down-4ma";
		usb_host_ehci = "/usb@ff440000";
		detect_grf = "/syscon@ff00b000";
		vcc_ddr = "/regulator-vcc-ddr";
		i2s_8ch_1_m1_sdo1_sdi3 = "/pinctrl/i2s_8ch_1_m1/i2s-8ch-1-m1-sdo1-sdi3";
		u2phy_host = "/syscon@ff008000/usb2phy@100/host-port";
		sdio_pwren = "/pinctrl/sdio/sdio-pwren";
		sfc = "/spi@ff4c0000";
		pdm_m1_sdi1 = "/pinctrl/pdm_m1/pdm-m1-sdi1";
		usb20_otg = "/usb@ff400000";
		spi1 = "/spi@ff130000";
		lcdc_rgb888_m0 = "/pinctrl/lcdc/lcdc-rgb888-m0";
		pwm6_pin_pull_down = "/pinctrl/pwm6/pwm6-pin-pull-down";
		pcfg_pull_none_2ma = "/pinctrl/pcfg-pull-none-2ma";
		emmc_pwren = "/pinctrl/emmc/emmc-pwren";
		vop_out = "/vop@ff2e0000/port";
		sdmmc = "/mmc@ff480000";
		flash_ale = "/pinctrl/flash/flash-ale";
		i2c0 = "/i2c@ff040000";
		soc_thermal = "/thermal-zones/soc-thermal";
		pwm6 = "/pwm@ff170020";
		uart4_rts_pin = "/pinctrl/uart4/uart4-rts-pin";
		spi0_mosi = "/pinctrl/spi0/spi0-mosi";
		uart0_rts = "/pinctrl/uart0/uart0-rts";
		pdm_m0_sdi3 = "/pinctrl/pdm_m0/pdm-m0-sdi3";
		pwm11 = "/pwm@ff160030";
		pcfg_pull_none_12ma = "/pinctrl/pcfg-pull-none-12ma";
		io_domains = "/grf@ff000000/io-domains";
		tsadc_otp_pin = "/pinctrl/tsadc/tsadc-otp-pin";
		i2s_8ch_0_sdo3 = "/pinctrl/i2s_8ch_0/i2s-8ch-0-sdo3";
		uart1_cts = "/pinctrl/uart1/uart1-cts";
		pwm2_pin = "/pinctrl/pwm2/pwm2-pin";
		bt_wake_host = "/pinctrl/bluetooth/bt-wake-host";
		flash_csn0 = "/pinctrl/flash/flash-csn0";
		heartbeat_led = "/pinctrl/leds/heartbeat-led";
		uart4_rts = "/pinctrl/uart4/uart4-rts";
		sdio = "/mmc@ff4a0000";
		codec = "/codec@ff560000";
		pwm6_pin = "/pinctrl/pwm6/pwm6-pin";
		spi0_clk = "/pinctrl/spi0/spi0-clk";
		pwm10_pin = "/pinctrl/pwm10/pwm10-pin";
		vop = "/vop@ff2e0000";
		pwm4_pin_pull_down = "/pinctrl/pwm4/pwm4-pin-pull-down";
		i2c0_xfer = "/pinctrl/i2c0/i2c0-xfer";
		pwm4 = "/pwm@ff170000";
		sdio_bus4 = "/pinctrl/sdio/sdio-bus4";
		emmc_bus4 = "/pinctrl/emmc/emmc-bus4";
		i2s_2ch_0_sdi = "/pinctrl/i2s_2ch_0/i2s-2ch-0-sdi";
		pdm_m0_sdi1 = "/pinctrl/pdm_m0/pdm-m0-sdi1";
		sdio_clk = "/pinctrl/sdio/sdio-clk";
		soc_crit = "/thermal-zones/soc-thermal/trips/soc-crit";
		i2s_8ch_0_sdo1 = "/pinctrl/i2s_8ch_0/i2s-8ch-0-sdo1";
		pcfg_pull_down = "/pinctrl/pcfg-pull-down";
		uart3 = "/serial@ff0d0000";
		pcfg_pull_up = "/pinctrl/pcfg-pull-up";
		dmac1 = "/dma-controller@ff2d0000";
		mac_refclk = "/pinctrl/gmac/mac-refclk";
		uart1_xfer = "/pinctrl/uart1/uart1-xfer";
		i2s_8ch_1_m1_mclk = "/pinctrl/i2s_8ch_1_m1/i2s-8ch-1-m1-mclk";
		cpu_dai = "/sound_i2s/simple-audio-card,cpu";
		pcfg_pull_none_8ma = "/pinctrl/pcfg-pull-none-8ma";
		pcfg_pull_up_4ma = "/pinctrl/pcfg-pull-up-4ma";
		sfc_clk = "/pinctrl/sfc/sfc-clk";
		vcc_1v8 = "/regulator-vcc-1v8";
		vad_sram = "/sram@fff80000/vad-sram@8000";
		sdmmc_cmd = "/pinctrl/sdmmc/sdmmc-cmd";
		vdd_core = "/regulator-vdd-core";
		i2s_8ch_0_lrcktx = "/pinctrl/i2s_8ch_0/i2s-8ch-0-lrcktx";
		i2s_8ch_0_sdi3 = "/pinctrl/i2s_8ch_0/i2s-8ch-0-sdi3";
		pwm2 = "/pwm@ff180020";
		CPU_SLEEP = "/cpus/idle-states/cpu-sleep";
		codec_dai = "/sound_i2s/simple-audio-card,codec";
		display_subsystem = "/display-subsystem";
		pwm2_pin_pull_down = "/pinctrl/pwm2/pwm2-pin-pull-down";
		gpio4 = "/pinctrl/gpio@ff260000";
		sdio_wrpt = "/pinctrl/sdio/sdio-wrpt";
		spi1m1_miso = "/pinctrl/spi1-m1/spi1m1-miso";
		cpu2 = "/cpus/cpu@2";
		spi2_miso = "/pinctrl/spi2/spi2-miso";
		uart1 = "/serial@ff0b0000";
		i2s_8ch_0_lrckrx = "/pinctrl/i2s_8ch_0/i2s-8ch-0-lrckrx";
		analog_sound = "/analog-sound";
		i2s_8ch_0_mclk = "/pinctrl/i2s_8ch_0/i2s-8ch-0-mclk";
		pdm_m2_sdi2 = "/pinctrl/pdm_m2/pdm-m2-sdi2";
		sdmmc_pwren = "/pinctrl/sdmmc/sdmmc-pwren";
		uart1_rts = "/pinctrl/uart1/uart1-rts";
		grf = "/grf@ff000000";
		pwm9_pin_pull_down = "/pinctrl/pwm9/pwm9-pin-pull-down";
		mac_rst = "/pinctrl/gmac/mac-rst";
		flash_rdy = "/pinctrl/flash/flash-rdy";
		pwm3_pin = "/pinctrl/pwm3/pwm3-pin";
		i2s_8ch_0_sdi1 = "/pinctrl/i2s_8ch_0/i2s-8ch-0-sdi1";
		rmiim1_pins = "/pinctrl/gmac-m1/rmiim1-pins";
		pwm0 = "/pwm@ff180000";
		uart0_xfer = "/pinctrl/uart0/uart0-xfer";
		i2s_8ch_1_m0_mclk = "/pinctrl/i2s_8ch_1_m0/i2s-8ch-1-m0-mclk";
		i2s_8ch_0_sclktx = "/pinctrl/i2s_8ch_0/i2s-8ch-0-sclktx";
		wifi_host_wake = "/pinctrl/sdio-pwrseq/wifi-host-wake";
		gpio2 = "/pinctrl/gpio@ff240000";
		bt_reg_on = "/pinctrl/bluetooth/bt-reg-on";
		pwm7_pin = "/pinctrl/pwm7/pwm7-pin";
		cpu0 = "/cpus/cpu@0";
		lcdc_ctl = "/pinctrl/lcdc/lcdc-ctl";
		spi1_clk = "/pinctrl/spi1/spi1-clk";
		pwm11_pin = "/pinctrl/pwm11/pwm11-pin";
		logic_thermal = "/thermal-zones/logic-thermal";
		i2s_8ch_1_m0_sdo3_sdi1 = "/pinctrl/i2s_8ch_1_m0/i2s-8ch-1-m0-sdo3_sdi1";
		pwm0_pin_pull_down = "/pinctrl/pwm0/pwm0-pin-pull-down";
		i2s_8ch_1_m1_sdo2_sdi2 = "/pinctrl/i2s_8ch_1_m1/i2s-8ch-1-m1-sdo2-sdi2";
		pdm_m2_sdi0 = "/pinctrl/pdm_m2/pdm-m2-sdi0";
	};

	usb@ff450000 {
		phy-names = "usb";
		interrupts = <0x00 0x48 0x04>;
		clocks = <0x02 0x9f 0x02 0xa0 0x0e>;
		compatible = "generic-ohci";
		status = "okay";
		phys = <0x54>;
		reg = <0x00 0xff450000 0x00 0x10000>;
		phandle = <0xb7>;
	};

	i2c@ff040000 {
		pinctrl-names = "default";
		#address-cells = <0x01>;
		pinctrl-0 = <0x10>;
		clock-names = "i2c", "pclk";
		interrupts = <0x00 0x0b 0x04>;
		clocks = <0x02 0x16 0x02 0xca>;
		#size-cells = <0x00>;
		compatible = "rockchip,rk3308-i2c", "rockchip,rk3399-i2c";
		status = "disabled";
		reg = <0x00 0xff040000 0x00 0x1000>;
		phandle = <0x8b>;
	};

	mmc@ff480000 {
		fifo-depth = <0x100>;
		pinctrl-names = "default";
		pinctrl-0 = <0x55 0x56 0x57 0x58>;
		clock-names = "biu", "ciu", "ciu-drive", "ciu-sample";
		cap-sd-highspeed;
		bus-width = <0x04>;
		card-detect-delay = <0xc8>;
		interrupts = <0x00 0x4c 0x04>;
		clocks = <0x02 0x9a 0x02 0x30 0x02 0x31 0x02 0x32>;
		vmmc-supply = <0x0c>;
		compatible = "rockchip,rk3308-dw-mshc", "rockchip,rk3288-dw-mshc";
		status = "okay";
		disable-wp;
		reg = <0x00 0xff480000 0x00 0x4000>;
		phandle = <0xb8>;
		max-frequency = <0x8f0d180>;
		cap-mmc-highspeed;
	};

	saradc@ff1e0000 {
		vref-supply = <0x0d>;
		clock-names = "saradc", "apb_pclk";
		resets = <0x02 0x46>;
		interrupts = <0x00 0x25 0x04>;
		clocks = <0x02 0x25 0x02 0xd2>;
		#io-channel-cells = <0x01>;
		compatible = "rockchip,rk3308-saradc", "rockchip,rk3399-saradc";
		status = "okay";
		reg = <0x00 0xff1e0000 0x00 0x100>;
		phandle = <0xa4>;
		reset-names = "saradc-apb";
	};

	regulator-vdd-log {
		regulator-max-microvolt = <0x100590>;
		regulator-boot-on;
		regulator-always-on;
		regulator-min-microvolt = <0x100590>;
		regulator-name = "vdd_log";
		compatible = "regulator-fixed";
		phandle = <0x11d>;
		vin-supply = <0x82>;
	};

	regulator-vcc-ddr {
		regulator-max-microvolt = <0x16e360>;
		regulator-boot-on;
		regulator-always-on;
		regulator-min-microvolt = <0x16e360>;
		regulator-name = "vcc_ddr";
		compatible = "regulator-fixed";
		phandle = <0x11c>;
		vin-supply = <0x82>;
	};

	memory {
		device_type = "memory";
		reg = <0x00 0x200000 0x00 0x1fe00000>;
	};
};
